AUTOSAR XML (schema 4-3-0)
package /E3_1_2_Premium
  system System: pnc-vector-length=7, pnc-vector-offset=1
    system mapping System_Mappings
      data-mappings:
        communication-direction=OUT, data-element=Infrastructure_RGS_VL_XIX_network_infrastructure_XIX_RGS_VL.Geltungsbereich_E3_1_2_Premium.SP_IF_NM_RGS_VL_Wakeup_XIX_Infrastructure_RGS_VL_XIX_network_infrastructure_XIX_RGS_VL.DE_NM_RGS_VL_Wakeup, system-signal=NM_RGS_VL_Wakeup
        communication-direction=OUT, data-element=Infrastructure_RGS_VL_XIX_network_infrastructure_XIX_RGS_VL.Geltungsbereich_E3_1_2_Premium.SP_IF_NM_RGS_VL_NM_aktiv_Diag_XIX_Infrastructure_RGS_VL_XIX_network_infrastructure_XIX_RGS_VL.DE_NM_RGS_VL_NM_aktiv_Diag, system-signal=NM_RGS_VL_NM_aktiv_Diag
        communication-direction=OUT, data-element=Infrastructure_RGS_VL_XIX_network_infrastructure_XIX_RGS_VL.Geltungsbereich_E3_1_2_Premium.SP_IF_NM_RGS_VL_FCAB_XIX_Infrastructure_RGS_VL_XIX_network_infrastructure_XIX_RGS_VL.DE_NM_RGS_VL_FCAB, system-signal=NM_RGS_VL_FCAB
        communication-direction=OUT, data-element=Infrastructure_RGS_VL_XIX_network_infrastructure_XIX_RGS_VL.Geltungsbereich_E3_1_2_Premium.SP_IF_NM_RGS_VL_NM_aktiv_KL15_XIX_Infrastructure_RGS_VL_XIX_network_infrastructure_XIX_RGS_VL.DE_NM_RGS_VL_NM_aktiv_KL15, system-signal=NM_RGS_VL_NM_aktiv_KL15
        communication-direction=OUT, data-element=Infrastructure_RGS_VL_XIX_network_infrastructure_XIX_RGS_VL.Geltungsbereich_E3_1_2_Premium.SP_IF_NM_RGS_VL_CBV_AWB_XIX_Infrastructure_RGS_VL_XIX_network_infrastructure_XIX_RGS_VL.DE_NM_RGS_VL_CBV_AWB, system-signal=NM_RGS_VL_CBV_AWB
        communication-direction=OUT, data-element=Infrastructure_RGS_VL_XIX_network_infrastructure_XIX_RGS_VL.Geltungsbereich_E3_1_2_Premium.SP_IF_NM_RGS_VL_CBV_CRI_XIX_Infrastructure_RGS_VL_XIX_network_infrastructure_XIX_RGS_VL.DE_NM_RGS_VL_CBV_CRI, system-signal=NM_RGS_VL_CBV_CRI
        communication-direction=OUT, data-element=Infrastructure_RGS_VL_XIX_network_infrastructure_XIX_RGS_VL.Geltungsbereich_E3_1_2_Premium.SP_IF_NM_RGS_VL_NM_aktiv_Tmin_XIX_Infrastructure_RGS_VL_XIX_network_infrastructure_XIX_RGS_VL.DE_NM_RGS_VL_NM_aktiv_Tmin, system-signal=NM_RGS_VL_NM_aktiv_Tmin
        communication-direction=OUT, data-element=Infrastructure_RGS_VL_XIX_network_infrastructure_XIX_RGS_VL.Geltungsbereich_E3_1_2_Premium.SP_IF_NM_RGS_VL_UDS_CC_XIX_Infrastructure_RGS_VL_XIX_network_infrastructure_XIX_RGS_VL.DE_NM_RGS_VL_UDS_CC, system-signal=NM_RGS_VL_UDS_CC
        communication-direction=OUT, data-element=Infrastructure_RGS_VL_XIX_network_infrastructure_XIX_RGS_VL.Geltungsbereich_E3_1_2_Premium.SP_IF_NM_RGS_VL_NM_State_XIX_Infrastructure_RGS_VL_XIX_network_infrastructure_XIX_RGS_VL.DE_NM_RGS_VL_NM_State, system-signal=NM_RGS_VL_NM_State
        communication-direction=OUT, data-element=Infrastructure_RGS_VL_XIX_network_infrastructure_XIX_RGS_VL.Geltungsbereich_E3_1_2_Premium.SP_IF_NM_RGS_VL_FCIB_XIX_Infrastructure_RGS_VL_XIX_network_infrastructure_XIX_RGS_VL.DE_NM_RGS_VL_FCIB, system-signal=NM_RGS_VL_FCIB
        communication-direction=OUT, data-element=Infrastructure_RGS_VL_XIX_network_infrastructure_XIX_RGS_VL.Geltungsbereich_E3_1_2_Premium.SP_IF_KN_RGS_VL_ECUKnockOutTimer_XIX_Infrastructure_RGS_VL_XIX_network_infrastructure_XIX_RGS_VL.DE_KN_RGS_VL_ECUKnockOutTimer, system-signal=KN_RGS_VL_ECUKnockOutTimer
        communication-direction=OUT, data-element=Infrastructure_RGS_VL_XIX_network_infrastructure_XIX_RGS_VL.Geltungsbereich_E3_1_2_Premium.SP_IF_KN_RGS_VL_BusKnockOut_XIX_Infrastructure_RGS_VL_XIX_network_infrastructure_XIX_RGS_VL.DE_KN_RGS_VL_BusKnockOut, system-signal=KN_RGS_VL_BusKnockOut
        communication-direction=OUT, data-element=Infrastructure_RGS_VL_XIX_network_infrastructure_XIX_RGS_VL.Geltungsbereich_E3_1_2_Premium.SP_IF_KN_RGS_VL_ECUKnockOut_XIX_Infrastructure_RGS_VL_XIX_network_infrastructure_XIX_RGS_VL.DE_KN_RGS_VL_ECUKnockOut, system-signal=KN_RGS_VL_ECUKnockOut
        communication-direction=OUT, data-element=Infrastructure_RGS_VL_XIX_network_infrastructure_XIX_RGS_VL.Geltungsbereich_E3_1_2_Premium.SP_IF_KN_RGS_VL_BusKnockOutTimer_XIX_Infrastructure_RGS_VL_XIX_network_infrastructure_XIX_RGS_VL.DE_KN_RGS_VL_BusKnockOutTimer, system-signal=KN_RGS_VL_BusKnockOutTimer
        communication-direction=IN, data-element=Infrastructure_RGS_VL_XIX_network_infrastructure_XIX_RGS_VL.Geltungsbereich_E3_1_2_Premium.RP_IF_NM_Airbag_01_FCAB_XIX_Infrastructure_RGS_VL_XIX_network_infrastructure_XIX_RGS_VL.DE_NM_Airbag_01_FCAB, system-signal=NM_Airbag_01_FCAB
        communication-direction=OUT, data-element=Infrastructure_RGS_VL_XIX_network_infrastructure_XIX_RGS_VL.Geltungsbereich_E3_1_2_Premium.SP_IF_NM_RGS_VL_SNI_10_XIX_Infrastructure_RGS_VL_XIX_network_infrastructure_XIX_RGS_VL.DE_NM_RGS_VL_SNI_10, system-signal=NM_RGS_VL_SNI_10
        communication-direction=OUT, data-element=Infrastructure_RGS_VL_XIX_network_infrastructure_XIX_RGS_VL.Geltungsbereich_E3_1_2_Premium.SP_IF_RGS_VL_Nachlauftyp_XIX_Infrastructure_RGS_VL_XIX_network_infrastructure_XIX_RGS_VL.DE_RGS_VL_Nachlauftyp, system-signal=RGS_VL_Nachlauftyp
        communication-direction=OUT, data-element=Infrastructure_RGS_VL_XIX_network_infrastructure_XIX_RGS_VL.Geltungsbereich_E3_1_2_Premium.SP_IF_NM_RGS_VL_NM_aktiv_Mot_aktiv_XIX_Infrastructure_RGS_VL_XIX_network_infrastructure_XIX_RGS_VL.DE_NM_RGS_VL_NM_aktiv_Mot_aktiv, system-signal=NM_RGS_VL_NM_aktiv_Mot_aktiv
        communication-direction=OUT, data-element=ReversiblenGurtStraffen_VL_XIX_Gurtfunktionen_XIX_RGS_VL.Geltungsbereich_E3_1_2_Premium.SP_IF_RGS_VL_Gurtgeschwindigkeit_XIX_ReversiblenGurtStraffen_VL_XIX_Gurtfunktionen_XIX_RGS_VL.DE_RGS_VL_Gurtgeschwindigkeit, system-signal=RGS_VL_Gurtgeschwindigkeit
        communication-direction=OUT, data-element=ReversiblenGurtStraffen_VL_XIX_Gurtfunktionen_XIX_RGS_VL.Geltungsbereich_E3_1_2_Premium.SP_IF_RGS_VL_Gurtbandauszug_XIX_ReversiblenGurtStraffen_VL_XIX_Gurtfunktionen_XIX_RGS_VL.DE_RGS_VL_Gurtbandauszug, system-signal=RGS_VL_Gurtbandauszug
        communication-direction=OUT, data-element=ReversiblenGurtStraffen_VL_XIX_Gurtfunktionen_XIX_RGS_VL.Geltungsbereich_E3_1_2_Premium.SP_IF_RGS_VL_InPos_XIX_ReversiblenGurtStraffen_VL_XIX_Gurtfunktionen_XIX_RGS_VL.DE_RGS_VL_InPos, system-signal=RGS_VL_InPos
        communication-direction=OUT, data-element=ReversiblenGurtStraffen_VL_XIX_Gurtfunktionen_XIX_RGS_VL.Geltungsbereich_E3_1_2_Premium.SP_IF_RGS_VL_Kommunikationsfehler_ASG_XIX_ReversiblenGurtStraffen_VL_XIX_Gurtfunktionen_XIX_RGS_VL.DE_RGS_VL_Kommunikationsfehler_ASG, system-signal=RGS_VL_Kommunikationsfehler_ASG
        communication-direction=OUT, data-element=ReversiblenGurtStraffen_VL_XIX_Gurtfunktionen_XIX_RGS_VL.Geltungsbereich_E3_1_2_Premium.SP_IF_RGS_VL_Crashabschaltung_XIX_ReversiblenGurtStraffen_VL_XIX_Gurtfunktionen_XIX_RGS_VL.DE_RGS_VL_Crashabschaltung, system-signal=RGS_VL_Crashabschaltung
        communication-direction=OUT, data-element=ReversiblenGurtStraffen_VL_XIX_Gurtfunktionen_XIX_RGS_VL.Geltungsbereich_E3_1_2_Premium.SP_IF_RGS_VL_Temp_XIX_ReversiblenGurtStraffen_VL_XIX_Gurtfunktionen_XIX_RGS_VL.DE_RGS_VL_Temp, system-signal=RGS_VL_Temp
        communication-direction=OUT, data-element=ReversiblenGurtStraffen_VL_XIX_Gurtfunktionen_XIX_RGS_VL.Geltungsbereich_E3_1_2_Premium.SP_IF_RGS_VL_keineStraffungUnterspg_XIX_ReversiblenGurtStraffen_VL_XIX_Gurtfunktionen_XIX_RGS_VL.DE_RGS_VL_keineStraffungUnterspg, system-signal=RGS_VL_keineStraffungUnterspg
        communication-direction=OUT, data-element=ReversiblenGurtStraffen_VL_XIX_Gurtfunktionen_XIX_RGS_VL.Geltungsbereich_E3_1_2_Premium.SP_IF_RGS_VL_Unterspannung_XIX_ReversiblenGurtStraffen_VL_XIX_Gurtfunktionen_XIX_RGS_VL.DE_RGS_VL_Unterspannung, system-signal=RGS_VL_Unterspannung
        communication-direction=OUT, data-element=ReversiblenGurtStraffen_VL_XIX_Gurtfunktionen_XIX_RGS_VL.Geltungsbereich_E3_1_2_Premium.SP_IF_RGS_VL_Uebertemperatur_defekt_XIX_ReversiblenGurtStraffen_VL_XIX_Gurtfunktionen_XIX_RGS_VL.DE_RGS_VL_Uebertemperatur_defekt, system-signal=RGS_VL_Uebertemperatur_defekt
        communication-direction=OUT, data-element=ReversiblenGurtStraffen_VL_XIX_Gurtfunktionen_XIX_RGS_VL.Geltungsbereich_E3_1_2_Premium.SP_IF_RGS_VL_EEPROM_Datensatzfehler_XIX_ReversiblenGurtStraffen_VL_XIX_Gurtfunktionen_XIX_RGS_VL.DE_RGS_VL_EEPROM_Datensatzfehler, system-signal=RGS_VL_EEPROM_Datensatzfehler
        communication-direction=OUT, data-element=ReversiblenGurtStraffen_VL_XIX_Gurtfunktionen_XIX_RGS_VL.Geltungsbereich_E3_1_2_Premium.SP_IF_RGS_VL_nicht_programmiert_XIX_ReversiblenGurtStraffen_VL_XIX_Gurtfunktionen_XIX_RGS_VL.DE_RGS_VL_nicht_programmiert, system-signal=RGS_VL_nicht_programmiert
        communication-direction=OUT, data-element=ReversiblenGurtStraffen_VL_XIX_Gurtfunktionen_XIX_RGS_VL.Geltungsbereich_E3_1_2_Premium.SP_IF_RGS_VL_Bauteilfehler_XIX_ReversiblenGurtStraffen_VL_XIX_Gurtfunktionen_XIX_RGS_VL.DE_RGS_VL_Bauteilfehler, system-signal=RGS_VL_Bauteilfehler
        communication-direction=OUT, data-element=ReversiblenGurtStraffen_VL_XIX_Gurtfunktionen_XIX_RGS_VL.Geltungsbereich_E3_1_2_Premium.SP_IF_RGS_VL_Max_Gurtlosezyklen_XIX_ReversiblenGurtStraffen_VL_XIX_Gurtfunktionen_XIX_RGS_VL.DE_RGS_VL_Max_Gurtlosezyklen, system-signal=RGS_VL_Max_Gurtlosezyklen
        communication-direction=OUT, data-element=ReversiblenGurtStraffen_VL_XIX_Gurtfunktionen_XIX_RGS_VL.Geltungsbereich_E3_1_2_Premium.SP_IF_RGS_VL_Ueberspannung_XIX_ReversiblenGurtStraffen_VL_XIX_Gurtfunktionen_XIX_RGS_VL.DE_RGS_VL_Ueberspannung, system-signal=RGS_VL_Ueberspannung
        communication-direction=OUT, data-element=ReversiblenGurtStraffen_VL_XIX_Gurtfunktionen_XIX_RGS_VL.Geltungsbereich_E3_1_2_Premium.SP_IF_RGS_VL_Motorfehler_XIX_ReversiblenGurtStraffen_VL_XIX_Gurtfunktionen_XIX_RGS_VL.DE_RGS_VL_Motorfehler, system-signal=RGS_VL_Motorfehler
        communication-direction=OUT, data-element=ReversiblenGurtStraffen_VL_XIX_Gurtfunktionen_XIX_RGS_VL.Geltungsbereich_E3_1_2_Premium.SP_IF_RGS_VL_Strom_XIX_ReversiblenGurtStraffen_VL_XIX_Gurtfunktionen_XIX_RGS_VL.DE_RGS_VL_Strom, system-signal=RGS_VL_Strom
        communication-direction=OUT, data-element=ReversiblenGurtStraffen_VL_XIX_Gurtfunktionen_XIX_RGS_VL.Geltungsbereich_E3_1_2_Premium.SP_IF_RGS_VL_Status_XIX_ReversiblenGurtStraffen_VL_XIX_Gurtfunktionen_XIX_RGS_VL.DE_RGS_VL_Status, system-signal=RGS_VL_Status
        communication-direction=OUT, data-element=ReversiblenGurtStraffen_VL_XIX_Gurtfunktionen_XIX_RGS_VL.Geltungsbereich_E3_1_2_Premium.SP_IF_RGS_VL_Max_Haptikzyklenfehler_XIX_ReversiblenGurtStraffen_VL_XIX_Gurtfunktionen_XIX_RGS_VL.DE_RGS_VL_Max_Haptikzyklenfehler, system-signal=RGS_VL_Max_Haptikzyklenfehler
        communication-direction=OUT, data-element=ReversiblenGurtStraffen_VL_XIX_Gurtfunktionen_XIX_RGS_VL.Geltungsbereich_E3_1_2_Premium.SP_IF_RGS_VL_Max_Straffzyklenfehler_XIX_ReversiblenGurtStraffen_VL_XIX_Gurtfunktionen_XIX_RGS_VL.DE_RGS_VL_Max_Straffzyklenfehler, system-signal=RGS_VL_Max_Straffzyklenfehler
        communication-direction=OUT, data-element=ReversiblenGurtStraffen_VL_XIX_Gurtfunktionen_XIX_RGS_VL.Geltungsbereich_E3_1_2_Premium.SP_IF_RGS_VL_keineStraffungUeberspg_XIX_ReversiblenGurtStraffen_VL_XIX_Gurtfunktionen_XIX_RGS_VL.DE_RGS_VL_keineStraffungUeberspg, system-signal=RGS_VL_keineStraffungUeberspg
        communication-direction=IN, data-element=ReversiblenGurtStraffen_VL_XIX_Gurtfunktionen_XIX_RGS_VL.Geltungsbereich_E3_1_2_Premium.RP_IF_RGS_VL_Anforderung_XIX_ReversiblenGurtStraffen_VL_XIX_Gurtfunktionen_XIX_RGS_VL.DE_RGS_VL_Anforderung, system-signal=RGS_VL_Anforderung
        communication-direction=IN, data-element=ReversiblenGurtStraffen_VL_XIX_Gurtfunktionen_XIX_RGS_VL.Geltungsbereich_E3_1_2_Premium.RP_IF_RGS_Nachlauf_allg_XIX_ReversiblenGurtStraffen_VL_XIX_Gurtfunktionen_XIX_RGS_VL.DE_RGS_Nachlauf_allg, system-signal=RGS_Nachlauf_allg
        communication-direction=IN, data-element=ReversiblenGurtStraffen_VL_XIX_Gurtfunktionen_XIX_RGS_VL.Geltungsbereich_E3_1_2_Premium.RP_IF_RGS_VL_Nachlauf_2_XIX_ReversiblenGurtStraffen_VL_XIX_Gurtfunktionen_XIX_RGS_VL.DE_RGS_VL_Nachlauf_2, system-signal=RGS_VL_Nachlauf_2
      pnc-mappings:
        pnc-identifier=8, wakeup-frame=[FT_NM_Airbag, FT_NM_RGS_VL]
        pnc-group=[RGS_VL_XIX_PNC_13_Airbag_Rx, RGS_VL_XIX_PNC_13_Airbag_Tx], pnc-identifier=20
      sw-mappings:
        swc to ecu mapping MAPPING_Infrastructure_RGS_VL_XIX_network_infrastructure_XIX_RGS_VL: component=Geltungsbereich_E3_1_2_Premium.Infrastructure_RGS_VL_XIX_network_infrastructure_XIX_RGS_VL, ecu-instance=RGS_VL
        swc to ecu mapping MAPPING_ReversiblenGurtStraffen_VL_XIX_Gurtfunktionen_XIX_RGS_VL: component=Geltungsbereich_E3_1_2_Premium.ReversiblenGurtStraffen_VL_XIX_Gurtfunktionen_XIX_RGS_VL, ecu-instance=RGS_VL
    root-software-compositions:
      root sw composition prototype Geltungsbereich_E3_1_2_Premium: software-composition=Geltungsbereich_E3_1_2_Premium
package /ECU
  ecu instance RGS_VL: associated-com-i-pdu-group=[RGS_VL_XIX_Airbag_SUBCANFD01_Rx, RGS_VL_XIX_Airbag_SUBCANFD01_Tx, RGS_VL_XIX_PNC_13_Airbag_Rx, RGS_VL_XIX_PNC_13_Airbag_Tx], diagnostic-address=1578, sleep-mode-supported=true, wake-up-over-bus-supported=true  # Reversibler Gurtstraffer vorn links
    can communication controller CT_Airbag_SUBCANFD01: can-controller-attributes=can-controller-configuration-requirements={can-controller-fd-requirements={max-number-of-time-quanta-per-bit=20, max-sample-point=80.0, max-sync-jump-width=20.0, max-trcv-delay-compensation-offset=80.0, min-number-of-time-quanta-per-bit=20, min-sample-point=80.0, min-sync-jump-width=20.0, min-trcv-delay-compensation-offset=80.0}, max-number-of-time-quanta-per-bit=20, max-sample-point=80.0, max-sync-jump-width=20.0, min-number-of-time-quanta-per-bit=20, min-sample-point=80.0, min-sync-jump-width=20.0}
    can communication connector CN_Airbag_SUBCANFD01: comm-controller=CT_Airbag_SUBCANFD01, pnc-gateway-type=NONE
package /Cluster
  can cluster Airbag_SUBCANFD01: baudrate=500000, protocol-name=CAN, protocol-version=2.0, can-fd-baudrate=500000  # Datenbus Erweitertes Sicherheitssystem
    can physical channel CHNL: comm-connectors=CN_Airbag_SUBCANFD01
      frame DIA_RGS_VL_Req_XIX_Airbag_SUBCANFD01: id 0x17FC162A, to RGS_VL, frame-length=8, can-addressing-mode=EXTENDED, can-fd-frame-support=true, can-frame-rx-behavior=CAN-FD, can-frame-tx-behavior=CAN-FD
        n pdu DIA_RGS_VL_Req_XIX_Airbag_SUBCANFD01: length=8
      frame DIA_RGS_VL_Resp_XIX_Airbag_SUBCANFD01: id 0x17FE162A, from RGS_VL, frame-length=8, can-addressing-mode=EXTENDED, can-fd-frame-support=true, can-frame-rx-behavior=CAN-FD, can-frame-tx-behavior=CAN-FD
        n pdu DIA_RGS_VL_Resp_XIX_Airbag_SUBCANFD01: length=8
      frame KN_RGS_VL_XIX_Airbag_SUBCANFD01: id 0x17F0005E, from RGS_VL, frame-length=16, can-addressing-mode=EXTENDED, can-fd-frame-support=true, can-frame-rx-behavior=CAN-FD, can-frame-tx-behavior=CAN-FD
        pdu KN_RGS_VL_XIX_Airbag_SUBCANFD01: length=16, transmission-mode-true-timing=cyclic-timing={time-offset=0.0, time-period=0.2}, unused-bit-pattern=0
          signal KN_RGS_VL_BusKnockOut_XIX_KN_RGS_VL_XIX_Airbag_SUBCANFD01: start 30, 2 bit, little-endian, data-type-policy=OVERRIDE, i-signal-type=PRIMITIVE, init-value=0, base-type=uint8, implementation-data-type=DT_KN_RGS_VL_BusKnockOut_XIX_KN_RGS_VL_XIX_Airbag_SUBCANFD01, compu {0=Cx0_Funktion_nicht_ausgeloest, 1=Cx1_Veto_aktiv, 3=Cx3_Funktion_deaktiviert, 2=Cx2_Funktion_ausgeloest}, range raw 0..3, transfer-property=PENDING  # Ausgabe des BusKnockout-Status
          signal KN_RGS_VL_BusKnockOutTimer_XIX_KN_RGS_VL_XIX_Airbag_SUBCANFD01: start 32, 8 bit, little-endian, data-type-policy=OVERRIDE, i-signal-type=PRIMITIVE, init-value=0, base-type=uint8, implementation-data-type=DT_KN_RGS_VL_BusKnockOutTimer_XIX_KN_RGS_VL_XIX_Airbag_SUBCANFD01, compu {phys=raw for raw 0..254, 255=Cxff_BusKnockOut_deaktiviert}, range phys 0..254, raw 0..255, transfer-property=PENDING  # Ausgabe des BusKnockOut-Timer
          signal KN_RGS_VL_ECUKnockOut_XIX_KN_RGS_VL_XIX_Airbag_SUBCANFD01: start 18, 2 bit, little-endian, data-type-policy=OVERRIDE, i-signal-type=PRIMITIVE, init-value=0, base-type=uint8, implementation-data-type=DT_KN_RGS_VL_ECUKnockOut_XIX_KN_RGS_VL_XIX_Airbag_SUBCANFD01, compu {2=Cx2_Funktion_ausgeloest, 3=Cx3_Funktion_deaktiviert, 1=Cx1_Veto_war_aktiv, 0=Cx0_Funktion_nicht_ausgeloest}, range raw 0..3, transfer-property=PENDING  # Ausgabe des ECUKnockout-Status
          signal KN_RGS_VL_ECUKnockOutTimer_XIX_KN_RGS_VL_XIX_Airbag_SUBCANFD01: start 24, 6 bit, little-endian, data-type-policy=OVERRIDE, i-signal-type=PRIMITIVE, init-value=0, base-type=uint8, implementation-data-type=DT_KN_RGS_VL_ECUKnockOutTimer_XIX_KN_RGS_VL_XIX_Airbag_SUBCANFD01, compu {phys=raw for raw 0..62, 63=Cx3f_ECUKnockOut_deaktiviert}, range phys 0..62, raw 0..63, transfer-property=PENDING  # Ausgabe des ECUKnockOut-Timer
          signal NM_RGS_VL_FCIB_XIX_KN_RGS_VL_XIX_Airbag_SUBCANFD01: start 40, 56 bit, opaque, data-type-policy=OVERRIDE, i-signal-type=ARRAY, init-value=7 x 0, base-type=uint8, implementation-data-type=DT_NM_RGS_VL_FCIB_XIX_KN_RGS_VL_XIX_Airbag_SUBCANFD01, compu {128=Cx80_reserviert, 8388608=Cx800000_Laden, 2048=Cx800_Airbag, 1=Cx1_CarWakeUp, 131072=Cx20000_Komfort2, 32768=Cx8000_Nahbereichszugang, 2=Cx2_Basisfunktion_AntriebFahrwerk, 0=Cx0_Init, 33554432=Cx2000000_MV_Aktivierung, 262144=Cx40000_Warnlampen, 512=Cx200_Fahrwerk, 256=Cx100_Antrieb, 1024=Cx400_Waehlhebel, 65536=Cx10000_Komfort1, 2097152=Cx200000_Thermomaagement, 16384=Cx4000_Sound, 4096=Cx1000_Fahrerassistenz, 2147483648=Cx80000000_reserviert, 8192=Cx2000_Displays, 4194304=Cx400000_VirtuelleAussenspiegel, 67108864=Cx4000000_Timermaster_Timer, 1073741824=Cx40000000_reserviert, 16777216=Cx1000000_HV_Aktivierung, 524288=Cx80000_Beleuchtung, 536870912=Cx20000000_reserviert, 268435456=Cx10000000_Multifunktionslankrad, 134217728=Cx8000000_Onboard_Tester_OBDC, 16=Cx10_Basisfunktion_KomfortKlimaLicht, 1048576=Cx100000_Innenklimatisierung, 32=Cx20_Basisfunktion_Querschnitt, 4=Cx4_Basisfunktion_Fahrerassistenz, 64=Cx40_Basisfunktion_Konnektivitaet, 8=Cx8_Basisfunktion_Infotainment}, range raw 0..2147483648, transfer-property=PENDING  # FCIB = Funktions-Cluster-Initialisierungs-Bits
          signal RGS_VL_Abschaltstufe_XIX_KN_RGS_VL_XIX_Airbag_SUBCANFD01: start 1, 1 bit, little-endian, data-type-policy=OVERRIDE, i-signal-type=PRIMITIVE, init-value=0, base-type=uint8, implementation-data-type=DT_RGS_VL_Abschaltstufe_XIX_KN_RGS_VL_XIX_Airbag_SUBCANFD01, compu {0=Cx0_keine_Einschraenkung, 1=Cx1_Funktionseinschraenkung}, range raw 0..1, transfer-property=PENDING  # Funktionseinschränkung aufgrund aktiver Abschaltstufe
          signal RGS_VL_KD_Fehler_XIX_KN_RGS_VL_XIX_Airbag_SUBCANFD01: start 23, 1 bit, little-endian, data-type-policy=OVERRIDE, i-signal-type=PRIMITIVE, init-value=0, base-type=uint8, implementation-data-type=DT_RGS_VL_KD_Fehler_XIX_KN_RGS_VL_XIX_Airbag_SUBCANFD01, compu {1=Cx1_KD_Fehler, 0=Cx0_kein_KD_Fehler}, range raw 0..1, transfer-property=PENDING
          signal RGS_VL_KompSchutz_XIX_KN_RGS_VL_XIX_Airbag_SUBCANFD01: start 0, 1 bit, little-endian, data-type-policy=OVERRIDE, i-signal-type=PRIMITIVE, init-value=0, base-type=uint8, implementation-data-type=DT_RGS_VL_KompSchutz_XIX_KN_RGS_VL_XIX_Airbag_SUBCANFD01, compu {1=Cx1_aktiv, 0=Cx0_inaktiv}, range raw 0..1, transfer-property=PENDING  # Funktionseinschränkung aufgrund Komponentenschutz aktiv
          signal RGS_VL_Lokalaktiv_XIX_KN_RGS_VL_XIX_Airbag_SUBCANFD01: start 21, 1 bit, little-endian, data-type-policy=OVERRIDE, i-signal-type=PRIMITIVE, init-value=0, base-type=uint8, implementation-data-type=DT_RGS_VL_Lokalaktiv_XIX_KN_RGS_VL_XIX_Airbag_SUBCANFD01, compu {0=Cx0_war_nicht_lokal_aktiv, 1=Cx1_war_lokal_aktiv}, range raw 0..1, transfer-property=PENDING  # Zeigt an ob das SG nach Klemme15 AUS und nach entsprechender MAX Aktivzeit noch aktiv war
          signal RGS_VL_Nachlauftyp_XIX_KN_RGS_VL_XIX_Airbag_SUBCANFD01: start 4, 4 bit, little-endian, data-type-policy=OVERRIDE, i-signal-type=PRIMITIVE, init-value=0, base-type=uint8, implementation-data-type=DT_RGS_VL_Nachlauftyp_XIX_KN_RGS_VL_XIX_Airbag_SUBCANFD01, compu {1=Cx1_Komm_nach_KL15_AUS, 2=Cx2_Komm_bei_KL15_AUS, 0=Cx0_Komm_bei_KL15_EIN}, range raw 0..2, transfer-property=PENDING  # Abgebildet wird die von der Hardware vorgegebene Möglichkeit, die Kommunikation nach Klemme 15 = AUS aufrecht zu erhalten. Es wird ein Init-Wert gesendet. 0 = Kommunikation nur bei KL15=EIN (kein Nachlauf, nicht weckfähig) 1 = Kommunikation nach KL15=AUS (Nachlauf, nicht weckfähig) 2 = Kommunikation bei KL15=AUS (Nachlauf, weckfähig) 3...15 = reserviert
          signal RGS_VL_SNI_10_XIX_KN_RGS_VL_XIX_Airbag_SUBCANFD01: start 8, 10 bit, little-endian, data-type-policy=OVERRIDE, i-signal-type=PRIMITIVE, init-value=94, base-type=uint16, implementation-data-type=DT_RGS_VL_SNI_10_XIX_KN_RGS_VL_XIX_Airbag_SUBCANFD01, compu {94=Cx5e_RGS_VL_SNI}, range raw 94, transfer-property=PENDING  # Source Node-Identifier (SNI) identifiziert den Sender der NM-Botschaft (Knotenadresse) eindeutig im Fahrzeug
          signal RGS_VL_Subsystemaktiv_XIX_KN_RGS_VL_XIX_Airbag_SUBCANFD01: start 22, 1 bit, little-endian, data-type-policy=OVERRIDE, i-signal-type=PRIMITIVE, init-value=0, base-type=uint8, implementation-data-type=DT_RGS_VL_Subsystemaktiv_XIX_KN_RGS_VL_XIX_Airbag_SUBCANFD01, compu {0=Cx0_Subsystem_war_nicht_lokalaktiv, 1=Cx1_war_lokalaktiv}, range raw 0..1, transfer-property=PENDING  # Zeigt an ob ein Subsystem des SGs nach Klemme15 AUS und nach entsprechender MAX Aktivzeit noch aktiv war
          signal RGS_VL_Transport_Mode_XIX_KN_RGS_VL_XIX_Airbag_SUBCANFD01: start 2, 1 bit, little-endian, data-type-policy=OVERRIDE, i-signal-type=PRIMITIVE, init-value=0, base-type=uint8, implementation-data-type=DT_RGS_VL_Transport_Mode_XIX_KN_RGS_VL_XIX_Airbag_SUBCANFD01, compu {0=Cx0_keine_Einschraenkung, 1=Cx1_Funktionseinschraenkung}, range raw 0..1, transfer-property=PENDING  # Funktionseinschränkung aufgrund aktivem Transport Mode und/oder Transport Schutz
      frame NM_Airbag_XIX_Airbag_SUBCANFD01: id 0x1B000015, to RGS_VL, frame-length=24, can-addressing-mode=EXTENDED, can-fd-frame-support=true, can-frame-rx-behavior=CAN-FD, can-frame-tx-behavior=CAN-FD, rx-identifier-range={lower-can-id=452984832, upper-can-id=452985855}
        nm pdu NM_Airbag_XIX_Airbag_SUBCANFD01: length=24
          signal NM_Airbag_01_CBV_AWB_XIX_NM_Airbag_XIX_Airbag_SUBCANFD01: start 4, 1 bit, little-endian, data-type-policy=OVERRIDE, i-signal-type=PRIMITIVE, init-value=0, base-type=uint8, implementation-data-type=DT_NM_Airbag_01_CBV_AWB_XIX_NM_Airbag_XIX_Airbag_SUBCANFD01, compu {1=Cx1_Aktiver_WakeUp, 0=Cx0_Passiver_WakeUp}, range raw 0..1, transfer-property=TRIGGERED  # Das Signal ist zu setzen, wenn das SG aktiv den Bus geweckt hat 0 = Passiver_WakeUp = SG hat das Netzwerk nicht aktiv geweckt 1 = Akitiver_WakeUp = SG hat das Netzwerk aktiv geweckt
          signal NM_Airbag_01_CBV_CRI_XIX_NM_Airbag_XIX_Airbag_SUBCANFD01: start 6, 1 bit, little-endian, data-type-policy=OVERRIDE, i-signal-type=PRIMITIVE, init-value=1, base-type=uint8, implementation-data-type=DT_NM_Airbag_01_CBV_CRI_XIX_NM_Airbag_XIX_Airbag_SUBCANFD01, compu {0=Cx0_NM_ohne_Clusteranforderungen, 1=Cx1_NM_mit_Clusteranforderungen}, range raw 0..1, transfer-property=TRIGGERED  # Das Signal ist dauerhaft gesetzt, wenn das NM-Layout Cluster- Anforderungen enthält
          signal NM_Airbag_01_FCAB_XIX_NM_Airbag_XIX_Airbag_SUBCANFD01: start 8, 56 bit, opaque, data-type-policy=OVERRIDE, i-signal-type=ARRAY, init-value=7 x 0, base-type=uint8, compu {8=Cx8_04_Basefunction_DrivingAssistance, 32=Cx20_06_Basefunction_ComfortLight, 4194304=Cx400000_23_Climate_PreHeater, 1048576=Cx100000_21_AirSuspension, 4096=Cx1000_13_Airbag, 524288=Cx80000_20_OptionalComfort, 4=Cx4_03_Basefunction_Chassis, 4294967296=Cx100000000_33_ExternalWirelessCommunication, 8388608=Cx800000_24_ThermoManagement, 2147483648=Cx80000000_32_OnlineAccess, 16777216=Cx1000000_25_AccessSystemSensors, 1024=Cx400_11_Chassis, 65536=Cx10000_17_Audio, 1073741824=Cx40000000_31_MultifunctionalSteeringWheel, 2097152=Cx200000_22_ExteriorLights, 8192=Cx2000_14_InfotainmentExtensions, 18014398509481984=Cx40000000000000_55_Dimming, 134217728=Cx8000000_28_OnboardTester_DataCollector, 36028797018963968=Cx80000000000000_56_ChargingStatus, 2048=Cx800_12_GearSelector, 2=Cx2_02_Basefunction_Powertrain, 16384=Cx4000_15_InstrumentclusterDisplay, 256=Cx100_09_reserved, 131072=Cx20000_18_VirtualSideMirrors, 17179869184=Cx400000000_53_Lock_Unlock, 33554432=Cx2000000_26_HighVoltage_Charging, 536870912=Cx20000000_30_EnergyManagement, 67108864=Cx4000000_27_Timemaster_Timer, 1=Cx1_01_CarWakeUp, 512=Cx200_10_Powertrain, 0=Cx0_Init, 262144=Cx40000_19_Doors_Hatches, 128=Cx80_08_Basefunction_Connectivity, 8589934592=Cx200000000_34_GPS_Localization, 64=Cx40_07_Basefunction_CrossSection, 32768=Cx8000_16_InfotainmentDisplay, 16=Cx10_05_Basefunction_Infotainment}, range raw 0..36028797018963968, transfer-property=TRIGGERED, to RGS_VL(timeout 2 s)  # FCAB = Funktions-Cluster-Aktiv-Bits
          signal NM_Airbag_01_NM_State_XIX_NM_Airbag_XIX_Airbag_SUBCANFD01: start 144, 6 bit, little-endian, data-type-policy=OVERRIDE, i-signal-type=PRIMITIVE, init-value=0, base-type=uint8, implementation-data-type=DT_NM_Airbag_01_NM_State_XIX_NM_Airbag_XIX_Airbag_SUBCANFD01, compu {16=Cx10_reserved, 2=Cx2_NM_RM_aus_PBSM, 4=Cx4_NM_NO_aus_RM, 0=Cx0_Init, 32=Cx20_reserved, 8=Cx8_NM_NO_aus_RS, 1=Cx1_NM_RM_aus_BSM}, range raw 0..32, transfer-property=TRIGGERED  # 1 = Zustand Repeat Message (<-- Bus-Sleep Mode) 2 = Zustand Repeat Message (<-- Prepare Bus-Sleep Mode) 4 = Zustand Normal Operation (<-- Repeat Message) 8 = Zustand Normal Operation (<-- Ready Sleep)
          signal NM_Airbag_01_NM_aktiv_Diag_XIX_NM_Airbag_XIX_Airbag_SUBCANFD01: start 161, 1 bit, little-endian, data-type-policy=OVERRIDE, i-signal-type=PRIMITIVE, init-value=0, base-type=uint8, implementation-data-type=DT_NM_Airbag_01_NM_aktiv_Diag_XIX_NM_Airbag_XIX_Airbag_SUBCANFD01, compu {1=Cx1_Diagnose_aktiv, 0=Cx0_Inaktiv}, range raw 0..1, transfer-property=TRIGGERED  # Diagnose befindet sich nach VW80124 in einer NonDefaultDiagnostic-Session, z.B. ExtendedDiagnostic-Session
          signal NM_Airbag_01_NM_aktiv_KL15_XIX_NM_Airbag_XIX_Airbag_SUBCANFD01: start 160, 1 bit, little-endian, data-type-policy=OVERRIDE, i-signal-type=PRIMITIVE, init-value=0, base-type=uint8, implementation-data-type=DT_NM_Airbag_01_NM_aktiv_KL15_XIX_NM_Airbag_XIX_Airbag_SUBCANFD01, compu {1=Cx1_KL15_EIN, 0=Cx0_Inaktiv}, range raw 0..1, transfer-property=TRIGGERED  # Steuergerät hat KL15-EIN erkannt
          signal NM_Airbag_01_NM_aktiv_Tmin_XIX_NM_Airbag_XIX_Airbag_SUBCANFD01: start 162, 1 bit, little-endian, data-type-policy=OVERRIDE, i-signal-type=PRIMITIVE, init-value=0, base-type=uint8, implementation-data-type=DT_NM_Airbag_01_NM_aktiv_Tmin_XIX_NM_Airbag_XIX_Airbag_SUBCANFD01, compu {0=Cx0_Inaktiv, 1=Cx1_Mindestaktivzeit}, range raw 0..1, transfer-property=TRIGGERED  # Mindestaktivzeit ist noch nicht abgelaufen (bei jedem Weckereignis wird die Mindestaktivzeit neu gestartet)
          signal NM_Airbag_01_SNI_10_XIX_NM_Airbag_XIX_Airbag_SUBCANFD01: start 128, 10 bit, little-endian, data-type-policy=OVERRIDE, i-signal-type=PRIMITIVE, init-value=21, base-type=uint16, implementation-data-type=DT_NM_Airbag_01_SNI_10_XIX_NM_Airbag_XIX_Airbag_SUBCANFD01, compu {21=Cx15_Airbag_01_SNI}, range raw 21, transfer-property=PENDING  # Source Node-Identifier (SNI) identifiziert den Sender der NM-Botschaft (Knotenadresse) eindeutig im Fahrzeug
          signal NM_Airbag_01_UDS_CC_XIX_NM_Airbag_XIX_Airbag_SUBCANFD01: start 151, 1 bit, little-endian, data-type-policy=OVERRIDE, i-signal-type=PRIMITIVE, init-value=0, base-type=uint8, implementation-data-type=DT_NM_Airbag_01_UDS_CC_XIX_NM_Airbag_XIX_Airbag_SUBCANFD01, compu {0=Cx0_Inaktiv, 1=Cx1_CC_aktiv}, range raw 0..1, transfer-property=TRIGGERED  # Funktionseinschränkung aufgrund aktivem UDS-Communication Control, siehe VW80124
          signal NM_Airbag_01_Wakeup_XIX_NM_Airbag_XIX_Airbag_SUBCANFD01: start 152, 8 bit, little-endian, data-type-policy=OVERRIDE, i-signal-type=PRIMITIVE, init-value=0, base-type=uint8, implementation-data-type=DT_NM_Airbag_01_Wakeup_XIX_NM_Airbag_XIX_Airbag_SUBCANFD01, compu {1=Cx1_Bus_Wakeup, 0=Cx0_Peripherie_Wakeup_Ursache_nicht_bekannt, 2=Cx2_KL15_HW}, range raw 0..2, transfer-property=TRIGGERED  # enthält die Weckursache; stehen mehrere Weckursachen parallel an, dann muss der kleinste Wert übertragen werden
          signal NM_aktiv_Ausloesefaehig_XIX_NM_Airbag_XIX_Airbag_SUBCANFD01: start 166, 1 bit, little-endian, data-type-policy=OVERRIDE, i-signal-type=PRIMITIVE, init-value=0, base-type=uint8, implementation-data-type=DT_NM_aktiv_Ausloesefaehig_XIX_NM_Airbag_XIX_Airbag_SUBCANFD01, compu {0=Cx0_Inaktiv, 1=Cx1_Aktiv}, range raw 0..1, transfer-property=TRIGGERED  # Steuergerät hat KL15-EIN erkannt
          signal NM_aktiv_Gurtschloss_XIX_NM_Airbag_XIX_Airbag_SUBCANFD01: start 167, 1 bit, little-endian, data-type-policy=OVERRIDE, i-signal-type=PRIMITIVE, init-value=0, base-type=uint8, implementation-data-type=DT_NM_aktiv_Gurtschloss_XIX_NM_Airbag_XIX_Airbag_SUBCANFD01, compu {0=Cx0_Inaktiv, 1=Cx1_Aktiv}, range raw 0..1, transfer-property=TRIGGERED  # Steuergerät hat KL15-EIN erkannt
          signal NM_aktiv_Kl15_unplausibel_XIX_NM_Airbag_XIX_Airbag_SUBCANFD01: start 164, 1 bit, little-endian, data-type-policy=OVERRIDE, i-signal-type=PRIMITIVE, init-value=0, base-type=uint8, implementation-data-type=DT_NM_aktiv_Kl15_unplausibel_XIX_NM_Airbag_XIX_Airbag_SUBCANFD01, compu {1=Cx1_Aktiv, 0=Cx0_Inaktiv}, range raw 0..1, transfer-property=TRIGGERED  # Steuergerät hat KL15-EIN erkannt
          signal NM_aktiv_Sitzbelegung_XIX_NM_Airbag_XIX_Airbag_SUBCANFD01: start 165, 1 bit, little-endian, data-type-policy=OVERRIDE, i-signal-type=PRIMITIVE, init-value=0, base-type=uint8, implementation-data-type=DT_NM_aktiv_Sitzbelegung_XIX_NM_Airbag_XIX_Airbag_SUBCANFD01, compu {0=Cx0_Inaktiv, 1=Cx1_Aktiv}, range raw 0..1, transfer-property=TRIGGERED  # Steuergerät hat KL15-EIN erkannt
      frame NM_RGS_VL_XIX_Airbag_SUBCANFD01: id 0x1B00005E, from RGS_VL, frame-length=24, can-addressing-mode=EXTENDED, can-fd-frame-support=true, can-frame-rx-behavior=CAN-FD, can-frame-tx-behavior=CAN-FD, rx-identifier-range={lower-can-id=452984832, upper-can-id=452985855}
        nm pdu NM_RGS_VL_XIX_Airbag_SUBCANFD01: length=24
          signal NM_RGS_VL_CBV_AWB_XIX_NM_RGS_VL_XIX_Airbag_SUBCANFD01: start 4, 1 bit, little-endian, data-type-policy=OVERRIDE, i-signal-type=PRIMITIVE, init-value=0, base-type=uint8, implementation-data-type=DT_NM_RGS_VL_CBV_AWB_XIX_NM_RGS_VL_XIX_Airbag_SUBCANFD01, compu {1=Cx1_Aktiver_WakeUp, 0=Cx0_Passiver_WakeUp}, range raw 0..1, transfer-property=TRIGGERED  # Das Signal ist zu setzen, wenn das SG aktiv den Bus geweckt hat 0 = Passiver_WakeUp = SG hat das Netzwerk nicht aktiv geweckt 1 = Akitiver_WakeUp = SG hat das Netzwerk aktiv geweckt
          signal NM_RGS_VL_CBV_CRI_XIX_NM_RGS_VL_XIX_Airbag_SUBCANFD01: start 6, 1 bit, little-endian, data-type-policy=OVERRIDE, i-signal-type=PRIMITIVE, init-value=1, base-type=uint8, implementation-data-type=DT_NM_RGS_VL_CBV_CRI_XIX_NM_RGS_VL_XIX_Airbag_SUBCANFD01, compu {0=Cx0_NM_ohne_Clusteranforderungen, 1=Cx1_NM_mit_Clusteranforderungen}, range raw 0..1, transfer-property=TRIGGERED  # Das Signal ist dauerhaft gesetzt, wenn das NM-Layout Cluster- Anforderungen enthält
          signal NM_RGS_VL_FCAB_XIX_NM_RGS_VL_XIX_Airbag_SUBCANFD01: start 8, 56 bit, opaque, data-type-policy=OVERRIDE, i-signal-type=ARRAY, init-value=7 x 0, base-type=uint8, implementation-data-type=DT_NM_RGS_VL_FCAB_XIX_NM_RGS_VL_XIX_Airbag_SUBCANFD01, compu {16777216=Cx1000000_25_AccessSystemSensors, 1048576=Cx100000_21_AirSuspension, 67108864=Cx4000000_27_Timemaster_Timer, 8589934592=Cx200000000_34_GPS_Localization, 8192=Cx2000_14_InfotainmentExtensions, 262144=Cx40000_19_Doors_Hatches, 128=Cx80_08_Basefunction_Connectivity, 2048=Cx800_12_GearSelector, 1024=Cx400_11_Chassis, 32768=Cx8000_16_InfotainmentDisplay, 524288=Cx80000_20_OptionalComfort, 36028797018963968=Cx80000000000000_56_ChargingStatus, 4194304=Cx400000_23_Climate_PreHeater, 2=Cx2_02_Basefunction_Powertrain, 2097152=Cx200000_22_ExteriorLights, 64=Cx40_07_Basefunction_CrossSection, 4096=Cx1000_13_Airbag, 512=Cx200_10_Powertrain, 18014398509481984=Cx40000000000000_55_Dimming, 33554432=Cx2000000_26_HighVoltage_Charging, 8388608=Cx800000_24_ThermoManagement, 256=Cx100_09_reserved, 17179869184=Cx400000000_53_Lock_Unlock, 4=Cx4_03_Basefunction_Chassis, 32=Cx20_06_Basefunction_ComfortLight, 536870912=Cx20000000_30_EnergyManagement, 65536=Cx10000_17_Audio, 1073741824=Cx40000000_31_MultifunctionalSteeringWheel, 8=Cx8_04_Basefunction_DrivingAssistance, 16384=Cx4000_15_InstrumentclusterDisplay, 1=Cx1_01_CarWakeUp, 2147483648=Cx80000000_32_OnlineAccess, 134217728=Cx8000000_28_OnboardTester_DataCollector, 131072=Cx20000_18_VirtualSideMirrors, 4294967296=Cx100000000_33_ExternalWirelessCommunication, 16=Cx10_05_Basefunction_Infotainment, 0=Cx0_Init}, range raw 0..36028797018963968, transfer-property=TRIGGERED-ON-CHANGE  # FCAB = Funktions-Cluster-Aktiv-Bits
          signal NM_RGS_VL_NM_State_XIX_NM_RGS_VL_XIX_Airbag_SUBCANFD01: start 144, 6 bit, little-endian, data-type-policy=OVERRIDE, i-signal-type=PRIMITIVE, init-value=0, base-type=uint8, implementation-data-type=DT_NM_RGS_VL_NM_State_XIX_NM_RGS_VL_XIX_Airbag_SUBCANFD01, compu {0=Cx0_Init, 32=Cx20_reserved, 2=Cx2_NM_RM_aus_PBSM, 1=Cx1_NM_RM_aus_BSM, 4=Cx4_NM_NO_aus_RM, 8=Cx8_NM_NO_aus_RS, 16=Cx10_reserved}, range raw 0..32, transfer-property=TRIGGERED  # 1 = Zustand Repeat Message (<-- Bus-Sleep Mode) 2 = Zustand Repeat Message (<-- Prepare Bus-Sleep Mode) 4 = Zustand Normal Operation (<-- Repeat Message) 8 = Zustand Normal Operation (<-- Ready Sleep)
          signal NM_RGS_VL_NM_aktiv_Diag_XIX_NM_RGS_VL_XIX_Airbag_SUBCANFD01: start 161, 1 bit, little-endian, data-type-policy=OVERRIDE, i-signal-type=PRIMITIVE, init-value=0, base-type=uint8, implementation-data-type=DT_NM_RGS_VL_NM_aktiv_Diag_XIX_NM_RGS_VL_XIX_Airbag_SUBCANFD01, compu {1=Cx1_Diagnose_aktiv, 0=Cx0_Inaktiv}, range raw 0..1, transfer-property=TRIGGERED  # Diagnose befindet sich nach VW80124 in einer NonDefaultDiagnostic-Session, z.B. ExtendedDiagnostic-Session
          signal NM_RGS_VL_NM_aktiv_KL15_XIX_NM_RGS_VL_XIX_Airbag_SUBCANFD01: start 160, 1 bit, little-endian, data-type-policy=OVERRIDE, i-signal-type=PRIMITIVE, init-value=0, base-type=uint8, implementation-data-type=DT_NM_RGS_VL_NM_aktiv_KL15_XIX_NM_RGS_VL_XIX_Airbag_SUBCANFD01, compu {0=Cx0_Inaktiv, 1=Cx1_KL15_EIN}, range raw 0..1, transfer-property=TRIGGERED  # Steuergerät hat KL15-EIN erkannt
          signal NM_RGS_VL_NM_aktiv_Mot_aktiv_XIX_NM_RGS_VL_XIX_Airbag_SUBCANFD01: start 163, 1 bit, little-endian, data-type-policy=OVERRIDE, i-signal-type=PRIMITIVE, init-value=0, base-type=uint8, implementation-data-type=DT_NM_RGS_VL_NM_aktiv_Mot_aktiv_XIX_NM_RGS_VL_XIX_Airbag_SUBCANFD01, compu {0=Cx0_Inaktiv, 1=Cx1_RGS_Motor_aktiv}, range raw 0..1, transfer-property=TRIGGERED  # Solange RGS Motor aktiv ist wird der SC-CAN wachgehalten
          signal NM_RGS_VL_NM_aktiv_Tmin_XIX_NM_RGS_VL_XIX_Airbag_SUBCANFD01: start 162, 1 bit, little-endian, data-type-policy=OVERRIDE, i-signal-type=PRIMITIVE, init-value=0, base-type=uint8, implementation-data-type=DT_NM_RGS_VL_NM_aktiv_Tmin_XIX_NM_RGS_VL_XIX_Airbag_SUBCANFD01, compu {1=Cx1_Mindestaktivzeit, 0=Cx0_Inaktiv}, range raw 0..1, transfer-property=TRIGGERED  # Mindestaktivzeit ist noch nicht abgelaufen (bei jedem Weckereignis wird die Mindestaktivzeit neu gestartet)
          signal NM_RGS_VL_SNI_10_XIX_NM_RGS_VL_XIX_Airbag_SUBCANFD01: start 128, 10 bit, little-endian, data-type-policy=OVERRIDE, i-signal-type=PRIMITIVE, init-value=94, base-type=uint16, implementation-data-type=DT_NM_RGS_VL_SNI_10_XIX_NM_RGS_VL_XIX_Airbag_SUBCANFD01, compu {94=Cx5e_RGS_VL_SNI}, range raw 94, transfer-property=TRIGGERED  # Source Node-Identifier (SNI) identifiziert den Sender der NM-Botschaft (Knotenadresse) eindeutig im Fahrzeug
          signal NM_RGS_VL_UDS_CC_XIX_NM_RGS_VL_XIX_Airbag_SUBCANFD01: start 151, 1 bit, little-endian, data-type-policy=OVERRIDE, i-signal-type=PRIMITIVE, init-value=0, base-type=uint8, implementation-data-type=DT_NM_RGS_VL_UDS_CC_XIX_NM_RGS_VL_XIX_Airbag_SUBCANFD01, compu {1=Cx1_CC_aktiv, 0=Cx0_Inaktiv}, range raw 0..1, transfer-property=TRIGGERED  # Funktionseinschränkung aufgrund aktivem UDS-Communication Control, siehe VW80124
          signal NM_RGS_VL_Wakeup_XIX_NM_RGS_VL_XIX_Airbag_SUBCANFD01: start 152, 8 bit, little-endian, data-type-policy=OVERRIDE, i-signal-type=PRIMITIVE, init-value=0, base-type=uint8, implementation-data-type=DT_NM_RGS_VL_Wakeup_XIX_NM_RGS_VL_XIX_Airbag_SUBCANFD01, compu {1=Cx1_Bus_Wakeup, 0=Cx0_Peripherie_Wakeup_Ursache_nicht_bekannt, 2=Cx2_KL15_HW}, range raw 0..2, transfer-property=TRIGGERED  # enthält die Weckursache; stehen mehrere Weckursachen parallel an, dann muss der kleinste Wert übertragen werden
      frame RGS_Anf_01_XIX_Airbag_SUBCANFD01: id 0x12DD551D, to RGS_VL, frame-length=16, can-addressing-mode=EXTENDED, can-fd-frame-support=true, can-frame-rx-behavior=CAN-FD, can-frame-tx-behavior=CAN-FD
        pdu RGS_Anf_01_XIX_Airbag_SUBCANFD01: length=16, minimum-delay=0.01, transmission-mode-true-timing={cyclic-timing={time-offset=0.0, time-period=0.5}, event-controlled-timing={number-of-repetitions=5, repetition-period=0.01}}, unused-bit-pattern=0
          signal RGS_HL_Anforderung_XIX_RGS_Anf_01_XIX_Airbag_SUBCANFD01: start 22, 5 bit, little-endian, data-type-policy=OVERRIDE, i-signal-type=PRIMITIVE, init-value=31, base-type=uint8, implementation-data-type=DT_RGS_HL_Anforderung_XIX_RGS_Anf_01_XIX_Airbag_SUBCANFD01, compu {25=Cx19_Loesekurve_1_Loesen_erlaubt (Loesekurve_1 (Loesen_erlaubt)), 13=Cxd_Straffung_13, 7=Cx7_Straffung_7, 9=Cx9_Straffung_9, 27=Cx1b_Funktion_beenden_Abbruch_Abwurf (Funktion_beenden (Abbruch/Abwurf)), 20=Cx14_Gurtparken_1, 24=Cx18_Antipatina, 21=Cx15_Gurtparken_2, 11=Cxb_Straffung_11, 6=Cx6_Straffung_6, 16=Cx10_Straffung_16, 1=Cx1_Straffung_1_maxGurtkraft (Straffung_1 (maxGurtkraft)), 0=Cx0_keine_Aktion, 26=Cx1a_Loesekurve_2, 23=Cx17_Gurtlosereduzierung, 22=Cx16_Crashabschaltung, 4=Cx4_Straffung_4_NGU (Straffung_4 (NGU)), 14=Cxe_Straffung_14, 2=Cx2_Straffung_2, 19=Cx13_Frei, 30=Cx1e_Init, 3=Cx3_Straffung_3, 8=Cx8_Straffung_8, 18=Cx12_Straffung_18, 5=Cx5_Straffung_5, 12=Cxc_Straffung_12, 15=Cxf_Straffung_15, 10=Cxa_Straffung_10, 17=Cx11_Straffung_17_Haptik (Straffung_17 (Haptik))}, range raw 0..30, transfer-property=TRIGGERED-ON-CHANGE  # Ansteuerung Reversibler Gurstraffer_HL
          signal RGS_HL_Nachlauf_2_XIX_RGS_Anf_01_XIX_Airbag_SUBCANFD01: start 34, 1 bit, little-endian, data-type-policy=OVERRIDE, i-signal-type=PRIMITIVE, init-value=0, base-type=uint8, implementation-data-type=DT_RGS_HL_Nachlauf_2_XIX_RGS_Anf_01_XIX_Airbag_SUBCANFD01, compu {1=Cx1_Nachlauf_2_aktiv, 0=Cx0_Nachlauf_2_nicht_aktiv}, range raw 0..1, transfer-property=PENDING  # RGS HL führt die Nachlaufzeit 2 aus
          signal RGS_HR_Anforderung_XIX_RGS_Anf_01_XIX_Airbag_SUBCANFD01: start 27, 5 bit, little-endian, data-type-policy=OVERRIDE, i-signal-type=PRIMITIVE, init-value=31, base-type=uint8, implementation-data-type=DT_RGS_HR_Anforderung_XIX_RGS_Anf_01_XIX_Airbag_SUBCANFD01, compu {6=Cx6_Straffung_6, 12=Cxc_Straffung_12, 11=Cxb_Straffung_11, 14=Cxe_Straffung_14, 17=Cx11_Straffung_17_Haptik (Straffung_17 (Haptik)), 26=Cx1a_Loesekurve_2, 25=Cx19_Loesekurve_1_Loesen_erlaubt (Loesekurve_1 (Loesen_erlaubt)), 16=Cx10_Straffung_16, 18=Cx12_Straffung_18, 7=Cx7_Straffung_7, 0=Cx0_keine_Aktion, 5=Cx5_Straffung_5, 8=Cx8_Straffung_8, 21=Cx15_Gurtparken_2, 10=Cxa_Straffung_10, 20=Cx14_Gurtparken_1, 15=Cxf_Straffung_15, 13=Cxd_Straffung_13, 4=Cx4_Straffung_4_NGU (Straffung_4 (NGU)), 3=Cx3_Straffung_3, 9=Cx9_Straffung_9, 22=Cx16_Crashabschaltung, 24=Cx18_Antipatina, 2=Cx2_Straffung_2, 23=Cx17_Gurtlosereduzierung, 1=Cx1_Straffung_1_maxGurtkraft (Straffung_1 (maxGurtkraft)), 27=Cx1b_Funktion_beenden_Abbruch_Abwurf (Funktion_beenden (Abbruch/Abwurf)), 30=Cx1e_Init, 19=Cx13_Frei}, range raw 0..30, transfer-property=TRIGGERED-ON-CHANGE  # Ansteuerung Reversibler Gurstraffer_VL
          signal RGS_HR_Nachlauf_2_XIX_RGS_Anf_01_XIX_Airbag_SUBCANFD01: start 35, 1 bit, little-endian, data-type-policy=OVERRIDE, i-signal-type=PRIMITIVE, init-value=0, base-type=uint8, implementation-data-type=DT_RGS_HR_Nachlauf_2_XIX_RGS_Anf_01_XIX_Airbag_SUBCANFD01, compu {0=Cx0_Nachlauf_2_nicht_aktiv, 1=Cx1_Nachlauf_2_aktiv}, range raw 0..1, transfer-property=PENDING  # RGS HR führt die Nachlaufzeit 2 aus
          signal RGS_Nachlauf_allg_XIX_RGS_Anf_01_XIX_Airbag_SUBCANFD01: start 36, 1 bit, little-endian, data-type-policy=OVERRIDE, i-signal-type=PRIMITIVE, init-value=0, base-type=uint8, implementation-data-type=DT_RGS_Nachlauf_allg_XIX_RGS_Anf_01_XIX_Airbag_SUBCANFD01, compu {1=Cx1_Nachlauf_aktiv, 0=Cx0_Nachlauf_nicht_aktiv}, range raw 0..1, transfer-property=PENDING, to RGS_VL(timeout 5 s)  # RGS führen Nachlauf aus
          signal RGS_VL_Anforderung_XIX_RGS_Anf_01_XIX_Airbag_SUBCANFD01: start 12, 5 bit, little-endian, data-type-policy=OVERRIDE, i-signal-type=PRIMITIVE, init-value=31, base-type=uint8, implementation-data-type=DT_RGS_VL_Anforderung_XIX_RGS_Anf_01_XIX_Airbag_SUBCANFD01, compu {0=Cx0_keine_Aktion, 18=Cx12_Straffung_18, 27=Cx1b_Funktion_beenden_Abbruch_Abwurf (Funktion_beenden (Abbruch/Abwurf)), 10=Cxa_Straffung_10, 19=Cx13_Frei, 26=Cx1a_Loesekurve_2, 30=Cx1e_Init, 23=Cx17_Gurtlosereduzierung, 13=Cxd_Straffung_13, 1=Cx1_Straffung_1_maxGurtkraft (Straffung_1 (maxGurtkraft)), 25=Cx19_Loesekurve_1_Loesen_erlaubt (Loesekurve_1 (Loesen_erlaubt)), 21=Cx15_Gurtparken_2, 20=Cx14_Gurtparken_1, 2=Cx2_Straffung_2, 8=Cx8_Straffung_8, 15=Cxf_Straffung_15, 9=Cx9_Straffung_9, 5=Cx5_Straffung_5, 6=Cx6_Straffung_6, 11=Cxb_Straffung_11, 22=Cx16_Crashabschaltung, 17=Cx11_Straffung_17_Haptik (Straffung_17 (Haptik)), 24=Cx18_Antipatina, 12=Cxc_Straffung_12, 3=Cx3_Straffung_3, 14=Cxe_Straffung_14, 16=Cx10_Straffung_16, 4=Cx4_Straffung_4_NGU (Straffung_4 (NGU)), 7=Cx7_Straffung_7}, range raw 0..30, transfer-property=TRIGGERED-ON-CHANGE, to RGS_VL(timeout 5 s)  # Ansteuerung Reversibler Gurstraffer_VL
          signal RGS_VL_Nachlauf_2_XIX_RGS_Anf_01_XIX_Airbag_SUBCANFD01: start 32, 1 bit, little-endian, data-type-policy=OVERRIDE, i-signal-type=PRIMITIVE, init-value=0, base-type=uint8, implementation-data-type=DT_RGS_VL_Nachlauf_2_XIX_RGS_Anf_01_XIX_Airbag_SUBCANFD01, compu {0=Cx0_Nachlauf_2_nicht_aktiv, 1=Cx1_Nachlauf_2_aktiv}, range raw 0..1, transfer-property=PENDING, to RGS_VL(timeout 5 s)  # RGS VL führt die Nachlaufzeit 2 aus
          signal RGS_VR_Anforderung_XIX_RGS_Anf_01_XIX_Airbag_SUBCANFD01: start 17, 5 bit, little-endian, data-type-policy=OVERRIDE, i-signal-type=PRIMITIVE, init-value=31, base-type=uint8, implementation-data-type=DT_RGS_VR_Anforderung_XIX_RGS_Anf_01_XIX_Airbag_SUBCANFD01, compu {26=Cx1a_Loesekurve_2, 10=Cxa_Straffung_10, 13=Cxd_Straffung_13, 25=Cx19_Loesekurve_1_Loesen_erlaubt (Loesekurve_1 (Loesen_erlaubt)), 3=Cx3_Straffung_3, 30=Cx1e_Init, 9=Cx9_Straffung_9, 21=Cx15_Gurtparken_2, 18=Cx12_Straffung_18, 5=Cx5_Straffung_5, 27=Cx1b_Funktion_beenden_Abbruch_Abwurf (Funktion_beenden (Abbruch/Abwurf)), 11=Cxb_Straffung_11, 4=Cx4_Straffung_4_NGU (Straffung_4 (NGU)), 17=Cx11_Straffung_17_Haptik (Straffung_17 (Haptik)), 0=Cx0_keine_Aktion, 24=Cx18_Antipatina, 14=Cxe_Straffung_14, 19=Cx13_Frei, 22=Cx16_Crashabschaltung, 16=Cx10_Straffung_16, 20=Cx14_Gurtparken_1, 15=Cxf_Straffung_15, 23=Cx17_Gurtlosereduzierung, 1=Cx1_Straffung_1_maxGurtkraft (Straffung_1 (maxGurtkraft)), 6=Cx6_Straffung_6, 12=Cxc_Straffung_12, 8=Cx8_Straffung_8, 7=Cx7_Straffung_7, 2=Cx2_Straffung_2}, range raw 0..30, transfer-property=TRIGGERED-ON-CHANGE  # Ansteuerung Reversibler Gurstraffer_VR
          signal RGS_VR_Nachlauf_2_XIX_RGS_Anf_01_XIX_Airbag_SUBCANFD01: start 33, 1 bit, little-endian, data-type-policy=OVERRIDE, i-signal-type=PRIMITIVE, init-value=0, base-type=uint8, implementation-data-type=DT_RGS_VR_Nachlauf_2_XIX_RGS_Anf_01_XIX_Airbag_SUBCANFD01, compu {1=Cx1_Nachlauf_2_aktiv, 0=Cx0_Nachlauf_2_nicht_aktiv}, range raw 0..1, transfer-property=PENDING  # RGS VR führt die Nachlaufzeit 2 aus
      frame RGS_VL_01_XIX_Airbag_SUBCANFD01: id 0x3D8, from RGS_VL, frame-length=16, can-addressing-mode=STANDARD, can-fd-frame-support=true, can-frame-rx-behavior=CAN-FD, can-frame-tx-behavior=CAN-FD
        pdu RGS_VL_01_XIX_Airbag_SUBCANFD01: length=16, minimum-delay=0.01, transmission-mode-true-timing={cyclic-timing={time-offset=0.0, time-period=0.5}, event-controlled-timing=number-of-repetitions=0}, unused-bit-pattern=0
          signal RGS_VL_Bauteilfehler_XIX_RGS_VL_01_XIX_Airbag_SUBCANFD01: start 37, 1 bit, little-endian, data-type-policy=OVERRIDE, i-signal-type=PRIMITIVE, init-value=1, base-type=uint8, implementation-data-type=DT_RGS_VL_Bauteilfehler_XIX_RGS_VL_01_XIX_Airbag_SUBCANFD01, compu {1=Cx1_Fehler_nicht_aktiv, 0=Cx0_Fehler_aktiv}, range raw 0..1, transfer-property=PENDING  # RGS VL übermittelt einen Bauteilfehler an den Safety Computer.
          signal RGS_VL_Crashabschaltung_XIX_RGS_VL_01_XIX_Airbag_SUBCANFD01: start 52, 1 bit, little-endian, data-type-policy=OVERRIDE, i-signal-type=PRIMITIVE, init-value=1, base-type=uint8, implementation-data-type=DT_RGS_VL_Crashabschaltung_XIX_RGS_VL_01_XIX_Airbag_SUBCANFD01, compu {1=Cx1_Fehler_nicht_aktiv, 0=Cx0_Fehler_aktiv}, range raw 0..1, transfer-property=PENDING  # RGS VL übermittelt an den Safety Computer, dass RGS aufgrund eines Crashevents den Straffvorgang abgebrochen hat.
          signal RGS_VL_EEPROM_Datensatzfehler_XIX_RGS_VL_01_XIX_Airbag_SUBCANFD01: start 55, 1 bit, little-endian, data-type-policy=OVERRIDE, i-signal-type=PRIMITIVE, init-value=1, base-type=uint8, implementation-data-type=DT_RGS_VL_EEPROM_Datensatzfehler_XIX_RGS_VL_01_XIX_Airbag_SUBCANFD01, compu {0=Cx0_Fehler_aktiv, 1=Cx1_Fehler_nicht_aktiv}, range raw 0..1, transfer-property=PENDING  # RGS VL übermittelt einen Datensatzfehler im EEPROM an den Safety Computer.
          signal RGS_VL_Gurtbandauszug_XIX_RGS_VL_01_XIX_Airbag_SUBCANFD01: start 22, 12 bit, little-endian, data-type-policy=OVERRIDE, i-signal-type=PRIMITIVE, init-value=4094, base-type=uint16, implementation-data-type=DT_RGS_VL_Gurtbandauszug_XIX_RGS_VL_01_XIX_Airbag_SUBCANFD01, invalid-value=Invalid_RGS_VL_Gurtbandauszug_XIX_RGS_VL_01_XIX_Airbag_SUBCANFD01:4095, compu {phys=raw*5-10235 for raw 0..4093, 4095=Cxfff_Fehler, 4094=Cxffe_Init; unit Unit_DegreOfArc}, range phys -10235..10230 Unit_DegreOfArc, raw 0..4095, unit=Unit_DegreOfArc, transfer-property=TRIGGERED-ON-CHANGE-WITHOUT-REPETITION  # Länge des Gurtbandauszugs
          signal RGS_VL_Gurtgeschwindigkeit_XIX_RGS_VL_01_XIX_Airbag_SUBCANFD01: start 12, 10 bit, little-endian, data-type-policy=OVERRIDE, i-signal-type=PRIMITIVE, init-value=511, base-type=uint16, implementation-data-type=DT_RGS_VL_Gurtgeschwindigkeit_XIX_RGS_VL_01_XIX_Airbag_SUBCANFD01, invalid-value=Invalid_RGS_VL_Gurtgeschwindigkeit_XIX_RGS_VL_01_XIX_Airbag_SUBCANFD01:1023, compu {phys=raw*5-2555 for raw 1..1021, 1023=Cx3ff_Fehler, 1022=Cx3fe_Auszuggeschwindigkeit_zu_hoch, 0=Cx0_Einlaufgeschwindigkeit_zu_hoch; unit Unit_DegreOfArcPerSecon}, range phys -2550..2550 Unit_DegreOfArcPerSecon, raw 0..1023, unit=Unit_DegreOfArcPerSecon, transfer-property=TRIGGERED-ON-CHANGE-WITHOUT-REPETITION  # positive Werte: Gurtbandauszug negative Werte: Gurtbandeinlauf
          signal RGS_VL_InPos_XIX_RGS_VL_01_XIX_Airbag_SUBCANFD01: start 56, 1 bit, little-endian, data-type-policy=OVERRIDE, i-signal-type=PRIMITIVE, init-value=0, base-type=uint8, implementation-data-type=DT_RGS_VL_InPos_XIX_RGS_VL_01_XIX_Airbag_SUBCANFD01, compu {1=Cx1_In_Position, 0=Cx0_Out_of_Position}, range raw 0..1, transfer-property=PENDING  # Der RGS setzt dieses Signal wenn der Insasse nach Fahrtbeginn an einen "normale" Position ruhig sitzt (keine Gurtlose mehr vorhanden)
          signal RGS_VL_Kommunikationsfehler_ASG_XIX_RGS_VL_01_XIX_Airbag_SUBCANFD01: start 48, 1 bit, little-endian, data-type-policy=OVERRIDE, i-signal-type=PRIMITIVE, init-value=1, base-type=uint8, implementation-data-type=DT_RGS_VL_Kommunikationsfehler_ASG_XIX_RGS_VL_01_XIX_Airbag_SUBCANFD01, compu {1=Cx1_Fehler_nicht_aktiv, 0=Cx0_Fehler_aktiv}, range raw 0..1, transfer-property=PENDING  # RGS VL übermittelt einen Kommunikationsfehler an den Safety Computer.
          signal RGS_VL_Max_Gurtlosezyklen_XIX_RGS_VL_01_XIX_Airbag_SUBCANFD01: start 39, 1 bit, little-endian, data-type-policy=OVERRIDE, i-signal-type=PRIMITIVE, init-value=1, base-type=uint8, implementation-data-type=DT_RGS_VL_Max_Gurtlosezyklen_XIX_RGS_VL_01_XIX_Airbag_SUBCANFD01, compu {1=Cx1_Fehler_nicht_aktiv, 0=Cx0_Fehler_aktiv}, range raw 0..1, transfer-property=PENDING  # RGS VL übermittelt einen Fehler an den Safety Computer wenn die maximalen Straffzyklen erreicht sind.
          signal RGS_VL_Max_Haptikzyklenfehler_XIX_RGS_VL_01_XIX_Airbag_SUBCANFD01: start 51, 1 bit, little-endian, data-type-policy=OVERRIDE, i-signal-type=PRIMITIVE, init-value=1, base-type=uint8, implementation-data-type=DT_RGS_VL_Max_Haptikzyklenfehler_XIX_RGS_VL_01_XIX_Airbag_SUBCANFD01, compu {1=Cx1_Fehler_nicht_aktiv (Fehler nicht aktiv), 0=Cx0_Fehler_aktiv (Fehler aktiv)}, range raw 0..1, transfer-property=PENDING  # Der RGS übermittelt an den Airbag dass die maximale Strazyklen für Haptik erreicht ist
          signal RGS_VL_Max_Straffzyklenfehler_XIX_RGS_VL_01_XIX_Airbag_SUBCANFD01: start 50, 1 bit, little-endian, data-type-policy=OVERRIDE, i-signal-type=PRIMITIVE, init-value=1, base-type=uint8, implementation-data-type=DT_RGS_VL_Max_Straffzyklenfehler_XIX_RGS_VL_01_XIX_Airbag_SUBCANFD01, compu {0=Cx0_Fehler_aktiv (Fehler aktiv), 1=Cx1_Fehler_nicht_aktiv (Fehler nicht aktiv)}, range raw 0..1, transfer-property=PENDING  # RGS VL übermittelt einen Fehler an den Safety Computer wenn die maximalen Straffzyklen erreicht sind.
          signal RGS_VL_Motorfehler_XIX_RGS_VL_01_XIX_Airbag_SUBCANFD01: start 54, 1 bit, little-endian, data-type-policy=OVERRIDE, i-signal-type=PRIMITIVE, init-value=1, base-type=uint8, implementation-data-type=DT_RGS_VL_Motorfehler_XIX_RGS_VL_01_XIX_Airbag_SUBCANFD01, compu {1=Cx1_Fehler_nicht_aktiv, 0=Cx0_Fehler_aktiv}, range raw 0..1, transfer-property=PENDING  # RGS VL übermittelt einen Motorfehler an den Safety Computer.
          signal RGS_VL_Status_XIX_RGS_VL_01_XIX_Airbag_SUBCANFD01: start 65, 5 bit, little-endian, data-type-policy=OVERRIDE, i-signal-type=PRIMITIVE, init-value=31, base-type=uint8, implementation-data-type=DT_RGS_VL_Status_XIX_RGS_VL_01_XIX_Airbag_SUBCANFD01, compu {2=Cx2_Straffung_2, 15=Cxf_Straffung_15, 29=Cx1d_Fehlerhafte_Straffdurchfuehrung, 14=Cxe_Straffung_14, 20=Cx14_Gurtparken_1, 6=Cx6_Straffung_6, 12=Cxc_Straffung_12, 28=Cx1c_Fehlerhafte_Straffanforderung, 22=Cx16_Crashabschaltung, 21=Cx15_Gurtparken_2, 30=Cx1e_Init, 9=Cx9_Straffung_9, 24=Cx18_Antipatina, 26=Cx1a_Loesekurve_2, 11=Cxb_Straffung_11, 0=Cx0_keine_Aktion, 18=Cx12_Straffung_18, 3=Cx3_Straffung_3, 19=Cx13_Frei, 7=Cx7_Straffung_7, 17=Cx11_Straffung_17_Haptik (Straffung_17 (Haptik)), 10=Cxa_Straffung_10, 5=Cx5_Straffung_5, 13=Cxd_Straffung_13, 8=Cx8_Straffung_8, 1=Cx1_Straffung_1_max_Gurtkraft (Straffung_1 (max Gurtkraft)), 4=Cx4_Straffung_4_NGU (Straffung_4 (NGU)), 23=Cx17_Gurtlosereduzierung, 16=Cx10_Straffung_16, 25=Cx19_Loesekurve_1_Loesen_erlaubt (Loesekurve_1 (Loesen_erlaubt)), 27=Cx1b_Funktion_beenden_Abbruch_Abwurf (Funktion_beenden (Abbruch/Abwurf))}, range raw 0..30, transfer-property=PENDING  # Rückantwort von RGS VL, welche Aktion durchgeführt wird
          signal RGS_VL_Strom_XIX_RGS_VL_01_XIX_Airbag_SUBCANFD01: start 57, 8 bit, little-endian, data-type-policy=OVERRIDE, i-signal-type=PRIMITIVE, init-value=254, base-type=uint8, implementation-data-type=DT_RGS_VL_Strom_XIX_RGS_VL_01_XIX_Airbag_SUBCANFD01, invalid-value=Invalid_RGS_VL_Strom_XIX_RGS_VL_01_XIX_Airbag_SUBCANFD01:255, compu {phys=raw*0.2 for raw 1..253, 255=Cxff_Fehler, 254=Cxfe_Init, 0=Cx0_Inaktiv; unit Unit_Amper}, range phys 0.2..50.6 Unit_Amper, raw 0..255, unit=Unit_Amper, transfer-property=PENDING  # RGS VL übermittelt Stromwert an den Safety Computer.
          signal RGS_VL_Temp_XIX_RGS_VL_01_XIX_Airbag_SUBCANFD01: start 40, 8 bit, little-endian, data-type-policy=OVERRIDE, i-signal-type=PRIMITIVE, init-value=254, base-type=uint8, implementation-data-type=DT_RGS_VL_Temp_XIX_RGS_VL_01_XIX_Airbag_SUBCANFD01, invalid-value=Invalid_RGS_VL_Temp_XIX_RGS_VL_01_XIX_Airbag_SUBCANFD01:255, compu {phys=raw*0.5-40 for raw 0..253, 255=Cxff_Fehler, 254=Cxfe_Init; unit Unit_DegreCelsi}, range phys -40..86.5 Unit_DegreCelsi, raw 0..255, unit=Unit_DegreCelsi, transfer-property=PENDING  # RGS VL übermittelt Temperatur an den Safety Computer.
          signal RGS_VL_Ueberspannung_XIX_RGS_VL_01_XIX_Airbag_SUBCANFD01: start 53, 1 bit, little-endian, data-type-policy=OVERRIDE, i-signal-type=PRIMITIVE, init-value=1, base-type=uint8, implementation-data-type=DT_RGS_VL_Ueberspannung_XIX_RGS_VL_01_XIX_Airbag_SUBCANFD01, compu {1=Cx1_Fehler_nicht_aktiv, 0=Cx0_Fehler_aktiv}, range raw 0..1, transfer-property=PENDING  # RGS hinten links übermittelt Ueberspannungsfehler an den Safety Computer.
          signal RGS_VL_Uebertemperatur_defekt_XIX_RGS_VL_01_XIX_Airbag_SUBCANFD01: start 36, 1 bit, little-endian, data-type-policy=OVERRIDE, i-signal-type=PRIMITIVE, init-value=1, base-type=uint8, implementation-data-type=DT_RGS_VL_Uebertemperatur_defekt_XIX_RGS_VL_01_XIX_Airbag_SUBCANFD01, compu {1=Cx1_Fehler_nicht_aktiv, 0=Cx0_Fehler_aktiv}, range raw 0..1, transfer-property=PENDING  # RGS VL übermittelt an den Safety Computer, dass RGS aufgrund eines Temperaturfehlers defekt ist.
          signal RGS_VL_Unterspannung_XIX_RGS_VL_01_XIX_Airbag_SUBCANFD01: start 49, 1 bit, little-endian, data-type-policy=OVERRIDE, i-signal-type=PRIMITIVE, init-value=1, base-type=uint8, implementation-data-type=DT_RGS_VL_Unterspannung_XIX_RGS_VL_01_XIX_Airbag_SUBCANFD01, compu {0=Cx0_Fehler_aktiv, 1=Cx1_Fehler_nicht_aktiv}, range raw 0..1, transfer-property=PENDING  # RGS VL übermittelt Unterspannungsfehler an den Safety Computer.
          signal RGS_VL_keineStraffungUeberspg_XIX_RGS_VL_01_XIX_Airbag_SUBCANFD01: start 38, 1 bit, little-endian, data-type-policy=OVERRIDE, i-signal-type=PRIMITIVE, init-value=1, base-type=uint8, implementation-data-type=DT_RGS_VL_keineStraffungUeberspg_XIX_RGS_VL_01_XIX_Airbag_SUBCANFD01, compu {0=Cx0_Fehler_aktiv, 1=Cx1_Fehler_nicht_aktiv}, range raw 0..1, transfer-property=PENDING  # RGS hinten links übermittelt an den Safety Computer, dass keine Straffung aufgrund Ueberspannung möglich ist.
          signal RGS_VL_keineStraffungUnterspg_XIX_RGS_VL_01_XIX_Airbag_SUBCANFD01: start 34, 1 bit, little-endian, data-type-policy=OVERRIDE, i-signal-type=PRIMITIVE, init-value=1, base-type=uint8, implementation-data-type=DT_RGS_VL_keineStraffungUnterspg_XIX_RGS_VL_01_XIX_Airbag_SUBCANFD01, compu {1=Cx1_Fehler_nicht_aktiv, 0=Cx0_Fehler_aktiv}, range raw 0..1, transfer-property=PENDING  # RGS VL übermittelt an den Safety Computer, dass keine Straffung aufgrund Unterspannung möglich ist.
          signal RGS_VL_nicht_programmiert_XIX_RGS_VL_01_XIX_Airbag_SUBCANFD01: start 35, 1 bit, little-endian, data-type-policy=OVERRIDE, i-signal-type=PRIMITIVE, init-value=1, base-type=uint8, implementation-data-type=DT_RGS_VL_nicht_programmiert_XIX_RGS_VL_01_XIX_Airbag_SUBCANFD01, compu {0=Cx0_Fehler_aktiv, 1=Cx1_Fehler_nicht_aktiv}, range raw 0..1, transfer-property=PENDING  # RGS VL übermittelt einen Fehler an den Safety Computer wenn keine Straffkurven programmiert sind
      pdu triggering PT_Airbag_SUBCANFD01_XIX_TPCHType_CANHS_Flash_DIA_XIX_402396714_XIX_402527786_XIX_Physical: pdu=DCM_Airbag_SUBCANFD01_XIX_TPCHType_CANHS_Flash_DIA_XIX_402396714_XIX_402527786_XIX_Physical, to RGS_VL
      pdu triggering PT_Airbag_SUBCANFD01_XIX_TPCHType_CANHS_Flash_DIA_XIX_402527786_XIX_402396714_XIX_Physical: pdu=DCM_Airbag_SUBCANFD01_XIX_TPCHType_CANHS_Flash_DIA_XIX_402527786_XIX_402396714_XIX_Physical, from RGS_VL
package /NmConfig
  nm config NmConfig
    can nm cluster NmCluster_Airbag_SUBCANFD01: communication-cluster=Airbag_SUBCANFD01, nm-channel-sleep-master=false, nm-synchronizing-network=false, nm-busload-reduction-active=false, nm-cbv-position=0, nm-immediate-nm-transmissions=0, nm-msg-cycle-time=0.2, nm-network-timeout=1.0, nm-remote-sleep-indication-time=0.5, nm-repeat-message-time=4.0, nm-wait-bus-sleep-time=0.75
      can nm node NmNode_RGS_VL_XIX_Airbag_SUBCANFD01: controller=CT_Airbag_SUBCANFD01, nm-if-ecu=NmEcu_RGS_VL, rx-nm-pdu=NM_Airbag_XIX_Airbag_SUBCANFD01, tx-nm-pdu=NM_RGS_VL_XIX_Airbag_SUBCANFD01, nm-msg-cycle-offset=0.0, nm-msg-reduced-time=0.0
    nm-if-ecus:
      nm ecu NmEcu_RGS_VL: ecu-instance=RGS_VL, nm-bus-synchronization-enabled=false, nm-com-control-enabled=false, nm-node-detection-enabled=false, nm-node-id-enabled=false, nm-user-data-enabled=true
package /PDU
  dcm i pdu DCM_Airbag_SUBCANFD01_XIX_TPCHType_CANHS_Flash_DIA_XIX_402396714_XIX_402527786_XIX_Physical: length=512, diag-pdu-type=DIAG-REQUEST
  dcm i pdu DCM_Airbag_SUBCANFD01_XIX_TPCHType_CANHS_Flash_DIA_XIX_402527786_XIX_402396714_XIX_Physical: length=512, diag-pdu-type=DIAG-RESPONSE
package /IPDUGroup
  4 x i signal i pdu group:
    RGS_VL_XIX_Airbag_SUBCANFD01_Rx: communication-direction=IN, communication-mode=CAN_Receive_All, i-signal-i-pdus=RGS_Anf_01_XIX_Airbag_SUBCANFD01
    RGS_VL_XIX_Airbag_SUBCANFD01_Tx: communication-direction=OUT, communication-mode=CAN_Transmit_All, i-signal-i-pdus=[KN_RGS_VL_XIX_Airbag_SUBCANFD01, RGS_VL_01_XIX_Airbag_SUBCANFD01]
    RGS_VL_XIX_PNC_13_Airbag_Rx: communication-direction=IN, communication-mode=Receive_13_Airbag, i-signal-i-pdus=RGS_Anf_01_XIX_Airbag_SUBCANFD01
    RGS_VL_XIX_PNC_13_Airbag_Tx: communication-direction=OUT, communication-mode=Transmit_13_Airbag, i-signal-i-pdus=RGS_VL_01_XIX_Airbag_SUBCANFD01
package /Unit
  4 x unit:
    Unit_Unit_Amper: display-name=Unit_Amper, factor-si-to-unit=1.0, physical-dimension=PD_siAmpere
    Unit_Unit_DegreCelsi: display-name=Unit_DegreCelsi, factor-si-to-unit=1.0, offset-si-to-unit=-273.2, physical-dimension=PD_siKelvin
    Unit_Unit_DegreOfArc: display-name=Unit_DegreOfArc, factor-si-to-unit=57.3, physical-dimension=PD_siRadiant
    Unit_Unit_DegreOfArcPerSecon: display-name=Unit_DegreOfArcPerSecon, factor-si-to-unit=57.3, physical-dimension=PD_siRadiantPerSecond
package /PhysicalDimension
  4 x physical dimension:
    PD_siAmpere: current-exp=1
    PD_siKelvin: temperature-exp=1
    PD_siRadiant: length-exp=0
    PD_siRadiantPerSecond: length-exp=0, time-exp=-1
package /TPConfig
  can tp config CanTPConfig_Airbag_SUBCANFD01: communication-cluster=Airbag_SUBCANFD01, can-tp-ecu=RGS_VL
    can tp address TA_402396714: tp-address=402396714
    can tp address TA_402527786: tp-address=402527786
    can tp channel TPC_Airbag_SUBCANFD01_XIX_TPCHType_CANHS_Flash_DIA_XIX_402396714_XIX_402527786_XIX_Physical: channel-id=968760377, channel-mode=HALF-DUPLEX-MODE
    can-tp-connection addressing-format=STANDARD, can-tp-channel=TPC_Airbag_SUBCANFD01_XIX_TPCHType_CANHS_Flash_DIA_XIX_402396714_XIX_402527786_XIX_Physical, cancellation=true, data-pdu=DIA_RGS_VL_Req_XIX_Airbag_SUBCANFD01, flow-control-pdu=DIA_RGS_VL_Resp_XIX_Airbag_SUBCANFD01, max-block-size=15, padding-activation=true, receiver=TPN_RGS_VL_XIX_Airbag_SUBCANFD01_XIX_402527786, ta-type=PHYSICAL, timeout-br=0.1, timeout-bs=1.0, timeout-cr=1.0, timeout-cs=0.2, tp-sdu=DCM_Airbag_SUBCANFD01_XIX_TPCHType_CANHS_Flash_DIA_XIX_402396714_XIX_402527786_XIX_Physical, transmitter=TPN_Airbag_6D_XIX_Airbag_SUBCANFD01_XIX_402396714:
      ident TPCN_Airbag_SUBCANFD01_XIX_TPCHType_CANHS_Flash_DIA_XIX_402396714_Airbag_6D_XIX_402527786_RGS_VL_XIX_Physical
    can-tp-connection addressing-format=STANDARD, can-tp-channel=TPC_Airbag_SUBCANFD01_XIX_TPCHType_CANHS_Flash_DIA_XIX_402396714_XIX_402527786_XIX_Physical, cancellation=true, data-pdu=DIA_RGS_VL_Resp_XIX_Airbag_SUBCANFD01, flow-control-pdu=DIA_RGS_VL_Req_XIX_Airbag_SUBCANFD01, max-block-size=15, padding-activation=true, receiver=TPN_Airbag_6D_XIX_Airbag_SUBCANFD01_XIX_402396714, ta-type=PHYSICAL, timeout-br=0.1, timeout-bs=1.0, timeout-cr=1.0, timeout-cs=0.2, tp-sdu=DCM_Airbag_SUBCANFD01_XIX_TPCHType_CANHS_Flash_DIA_XIX_402527786_XIX_402396714_XIX_Physical, transmitter=TPN_RGS_VL_XIX_Airbag_SUBCANFD01_XIX_402527786:
      ident TPCN_Airbag_SUBCANFD01_XIX_TPCHType_CANHS_Flash_DIA_XIX_402527786_RGS_VL_XIX_402396714_Airbag_6D_XIX_Physical
    can tp node TPN_Airbag_6D_XIX_Airbag_SUBCANFD01_XIX_402396714: max-fc-wait=15, st-min=0.005, timeout-ar=1.0, timeout-as=1.0, tp-address=TA_402396714
    can tp node TPN_RGS_VL_XIX_Airbag_SUBCANFD01_XIX_402527786: connector=CN_Airbag_SUBCANFD01, max-fc-wait=15, st-min=0.005, timeout-ar=1.0, timeout-as=1.0, tp-address=TA_402527786
package /Interfaces
  41 x sender receiver interface:
    IF_KN_RGS_VL_BusKnockOut
      data DE_KN_RGS_VL_BusKnockOut: type=DT_KN_RGS_VL_BusKnockOut_XIX_KN_RGS_VL_XIX_Airbag_SUBCANFD01
    IF_KN_RGS_VL_BusKnockOutTimer
      data DE_KN_RGS_VL_BusKnockOutTimer: type=DT_KN_RGS_VL_BusKnockOutTimer_XIX_KN_RGS_VL_XIX_Airbag_SUBCANFD01
    IF_KN_RGS_VL_ECUKnockOut
      data DE_KN_RGS_VL_ECUKnockOut: type=DT_KN_RGS_VL_ECUKnockOut_XIX_KN_RGS_VL_XIX_Airbag_SUBCANFD01
    IF_KN_RGS_VL_ECUKnockOutTimer
      data DE_KN_RGS_VL_ECUKnockOutTimer: type=DT_KN_RGS_VL_ECUKnockOutTimer_XIX_KN_RGS_VL_XIX_Airbag_SUBCANFD01
    IF_NM_Airbag_01_FCAB
      data DE_NM_Airbag_01_FCAB: type=DT_NM_Airbag_01_FCAB_XIX_NM_Airbag_XIX_Airbag_SUBCANFD01
    IF_NM_RGS_VL_CBV_AWB
      data DE_NM_RGS_VL_CBV_AWB: type=DT_NM_RGS_VL_CBV_AWB_XIX_NM_RGS_VL_XIX_Airbag_SUBCANFD01
    IF_NM_RGS_VL_CBV_CRI
      data DE_NM_RGS_VL_CBV_CRI: type=DT_NM_RGS_VL_CBV_CRI_XIX_NM_RGS_VL_XIX_Airbag_SUBCANFD01
    IF_NM_RGS_VL_FCAB
      data DE_NM_RGS_VL_FCAB: type=DT_NM_RGS_VL_FCAB_XIX_NM_RGS_VL_XIX_Airbag_SUBCANFD01
    IF_NM_RGS_VL_FCIB
      data DE_NM_RGS_VL_FCIB: type=DT_NM_RGS_VL_FCIB_XIX_KN_RGS_VL_XIX_Airbag_SUBCANFD01
    IF_NM_RGS_VL_NM_State
      data DE_NM_RGS_VL_NM_State: type=DT_NM_RGS_VL_NM_State_XIX_NM_RGS_VL_XIX_Airbag_SUBCANFD01
    IF_NM_RGS_VL_NM_aktiv_Diag
      data DE_NM_RGS_VL_NM_aktiv_Diag: type=DT_NM_RGS_VL_NM_aktiv_Diag_XIX_NM_RGS_VL_XIX_Airbag_SUBCANFD01
    IF_NM_RGS_VL_NM_aktiv_KL15
      data DE_NM_RGS_VL_NM_aktiv_KL15: type=DT_NM_RGS_VL_NM_aktiv_KL15_XIX_NM_RGS_VL_XIX_Airbag_SUBCANFD01
    IF_NM_RGS_VL_NM_aktiv_Mot_aktiv
      data DE_NM_RGS_VL_NM_aktiv_Mot_aktiv: type=DT_NM_RGS_VL_NM_aktiv_Mot_aktiv_XIX_NM_RGS_VL_XIX_Airbag_SUBCANFD01
    IF_NM_RGS_VL_NM_aktiv_Tmin
      data DE_NM_RGS_VL_NM_aktiv_Tmin: type=DT_NM_RGS_VL_NM_aktiv_Tmin_XIX_NM_RGS_VL_XIX_Airbag_SUBCANFD01
    IF_NM_RGS_VL_SNI_10
      data DE_NM_RGS_VL_SNI_10: type=DT_NM_RGS_VL_SNI_10_XIX_NM_RGS_VL_XIX_Airbag_SUBCANFD01
    IF_NM_RGS_VL_UDS_CC
      data DE_NM_RGS_VL_UDS_CC: type=DT_NM_RGS_VL_UDS_CC_XIX_NM_RGS_VL_XIX_Airbag_SUBCANFD01
    IF_NM_RGS_VL_Wakeup
      data DE_NM_RGS_VL_Wakeup: type=DT_NM_RGS_VL_Wakeup_XIX_NM_RGS_VL_XIX_Airbag_SUBCANFD01
    IF_RGS_Nachlauf_allg
      data DE_RGS_Nachlauf_allg: type=DT_RGS_Nachlauf_allg_XIX_RGS_Anf_01_XIX_Airbag_SUBCANFD01
    IF_RGS_VL_Anforderung
      data DE_RGS_VL_Anforderung: type=DT_RGS_VL_Anforderung_XIX_RGS_Anf_01_XIX_Airbag_SUBCANFD01
    IF_RGS_VL_Bauteilfehler
      data DE_RGS_VL_Bauteilfehler: type=DT_RGS_VL_Bauteilfehler_XIX_RGS_VL_01_XIX_Airbag_SUBCANFD01
    IF_RGS_VL_Crashabschaltung
      data DE_RGS_VL_Crashabschaltung: type=DT_RGS_VL_Crashabschaltung_XIX_RGS_VL_01_XIX_Airbag_SUBCANFD01
    IF_RGS_VL_EEPROM_Datensatzfehler
      data DE_RGS_VL_EEPROM_Datensatzfehler: type=DT_RGS_VL_EEPROM_Datensatzfehler_XIX_RGS_VL_01_XIX_Airbag_SUBCANFD01
    IF_RGS_VL_Gurtbandauszug
      data DE_RGS_VL_Gurtbandauszug: type=DT_RGS_VL_Gurtbandauszug_XIX_RGS_VL_01_XIX_Airbag_SUBCANFD01
    IF_RGS_VL_Gurtgeschwindigkeit
      data DE_RGS_VL_Gurtgeschwindigkeit: type=DT_RGS_VL_Gurtgeschwindigkeit_XIX_RGS_VL_01_XIX_Airbag_SUBCANFD01
    IF_RGS_VL_InPos
      data DE_RGS_VL_InPos: type=DT_RGS_VL_InPos_XIX_RGS_VL_01_XIX_Airbag_SUBCANFD01
    IF_RGS_VL_Kommunikationsfehler_ASG
      data DE_RGS_VL_Kommunikationsfehler_ASG: type=DT_RGS_VL_Kommunikationsfehler_ASG_XIX_RGS_VL_01_XIX_Airbag_SUBCANFD01
    IF_RGS_VL_Max_Gurtlosezyklen
      data DE_RGS_VL_Max_Gurtlosezyklen: type=DT_RGS_VL_Max_Gurtlosezyklen_XIX_RGS_VL_01_XIX_Airbag_SUBCANFD01
    IF_RGS_VL_Max_Haptikzyklenfehler
      data DE_RGS_VL_Max_Haptikzyklenfehler: type=DT_RGS_VL_Max_Haptikzyklenfehler_XIX_RGS_VL_01_XIX_Airbag_SUBCANFD01
    IF_RGS_VL_Max_Straffzyklenfehler
      data DE_RGS_VL_Max_Straffzyklenfehler: type=DT_RGS_VL_Max_Straffzyklenfehler_XIX_RGS_VL_01_XIX_Airbag_SUBCANFD01
    IF_RGS_VL_Motorfehler
      data DE_RGS_VL_Motorfehler: type=DT_RGS_VL_Motorfehler_XIX_RGS_VL_01_XIX_Airbag_SUBCANFD01
    IF_RGS_VL_Nachlauf_2
      data DE_RGS_VL_Nachlauf_2: type=DT_RGS_VL_Nachlauf_2_XIX_RGS_Anf_01_XIX_Airbag_SUBCANFD01
    IF_RGS_VL_Nachlauftyp
      data DE_RGS_VL_Nachlauftyp: type=DT_RGS_VL_Nachlauftyp_XIX_KN_RGS_VL_XIX_Airbag_SUBCANFD01
    IF_RGS_VL_Status
      data DE_RGS_VL_Status: type=DT_RGS_VL_Status_XIX_RGS_VL_01_XIX_Airbag_SUBCANFD01
    IF_RGS_VL_Strom
      data DE_RGS_VL_Strom: type=DT_RGS_VL_Strom_XIX_RGS_VL_01_XIX_Airbag_SUBCANFD01
    IF_RGS_VL_Temp
      data DE_RGS_VL_Temp: type=DT_RGS_VL_Temp_XIX_RGS_VL_01_XIX_Airbag_SUBCANFD01
    IF_RGS_VL_Ueberspannung
      data DE_RGS_VL_Ueberspannung: type=DT_RGS_VL_Ueberspannung_XIX_RGS_VL_01_XIX_Airbag_SUBCANFD01
    IF_RGS_VL_Uebertemperatur_defekt
      data DE_RGS_VL_Uebertemperatur_defekt: type=DT_RGS_VL_Uebertemperatur_defekt_XIX_RGS_VL_01_XIX_Airbag_SUBCANFD01
    IF_RGS_VL_Unterspannung
      data DE_RGS_VL_Unterspannung: type=DT_RGS_VL_Unterspannung_XIX_RGS_VL_01_XIX_Airbag_SUBCANFD01
    IF_RGS_VL_keineStraffungUeberspg
      data DE_RGS_VL_keineStraffungUeberspg: type=DT_RGS_VL_keineStraffungUeberspg_XIX_RGS_VL_01_XIX_Airbag_SUBCANFD01
    IF_RGS_VL_keineStraffungUnterspg
      data DE_RGS_VL_keineStraffungUnterspg: type=DT_RGS_VL_keineStraffungUnterspg_XIX_RGS_VL_01_XIX_Airbag_SUBCANFD01
    IF_RGS_VL_nicht_programmiert
      data DE_RGS_VL_nicht_programmiert: type=DT_RGS_VL_nicht_programmiert_XIX_RGS_VL_01_XIX_Airbag_SUBCANFD01
package /ComponentTypes
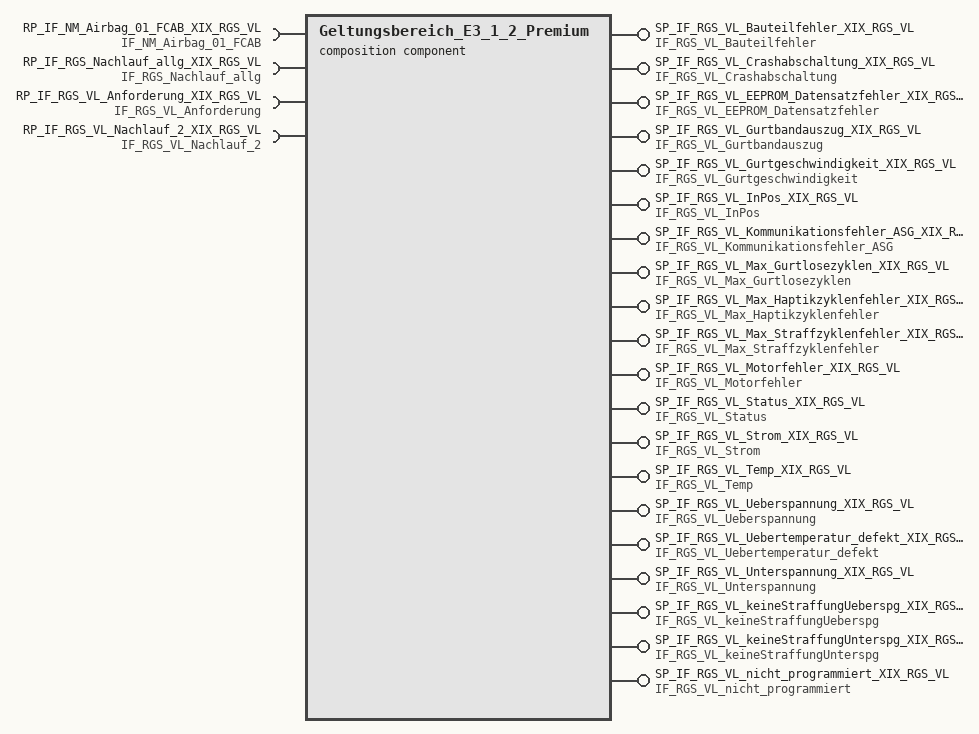
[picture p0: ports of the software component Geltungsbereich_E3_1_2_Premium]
  composition sw component type Geltungsbereich_E3_1_2_Premium
    4 x require port:
      RP_IF_NM_Airbag_01_FCAB_XIX_RGS_VL: required-interface=IF_NM_Airbag_01_FCAB
      RP_IF_RGS_Nachlauf_allg_XIX_RGS_VL: required-interface=IF_RGS_Nachlauf_allg
      RP_IF_RGS_VL_Anforderung_XIX_RGS_VL: required-interface=IF_RGS_VL_Anforderung
      RP_IF_RGS_VL_Nachlauf_2_XIX_RGS_VL: required-interface=IF_RGS_VL_Nachlauf_2
    20 x provide port:
      SP_IF_RGS_VL_Bauteilfehler_XIX_RGS_VL: provided-interface=IF_RGS_VL_Bauteilfehler
      SP_IF_RGS_VL_Crashabschaltung_XIX_RGS_VL: provided-interface=IF_RGS_VL_Crashabschaltung
      SP_IF_RGS_VL_EEPROM_Datensatzfehler_XIX_RGS_VL: provided-interface=IF_RGS_VL_EEPROM_Datensatzfehler
      SP_IF_RGS_VL_Gurtbandauszug_XIX_RGS_VL: provided-interface=IF_RGS_VL_Gurtbandauszug
      SP_IF_RGS_VL_Gurtgeschwindigkeit_XIX_RGS_VL: provided-interface=IF_RGS_VL_Gurtgeschwindigkeit
      SP_IF_RGS_VL_InPos_XIX_RGS_VL: provided-interface=IF_RGS_VL_InPos
      SP_IF_RGS_VL_Kommunikationsfehler_ASG_XIX_RGS_VL: provided-interface=IF_RGS_VL_Kommunikationsfehler_ASG
      SP_IF_RGS_VL_Max_Gurtlosezyklen_XIX_RGS_VL: provided-interface=IF_RGS_VL_Max_Gurtlosezyklen
      SP_IF_RGS_VL_Max_Haptikzyklenfehler_XIX_RGS_VL: provided-interface=IF_RGS_VL_Max_Haptikzyklenfehler
      SP_IF_RGS_VL_Max_Straffzyklenfehler_XIX_RGS_VL: provided-interface=IF_RGS_VL_Max_Straffzyklenfehler
      SP_IF_RGS_VL_Motorfehler_XIX_RGS_VL: provided-interface=IF_RGS_VL_Motorfehler
      SP_IF_RGS_VL_Status_XIX_RGS_VL: provided-interface=IF_RGS_VL_Status
      SP_IF_RGS_VL_Strom_XIX_RGS_VL: provided-interface=IF_RGS_VL_Strom
      SP_IF_RGS_VL_Temp_XIX_RGS_VL: provided-interface=IF_RGS_VL_Temp
      SP_IF_RGS_VL_Ueberspannung_XIX_RGS_VL: provided-interface=IF_RGS_VL_Ueberspannung
      SP_IF_RGS_VL_Uebertemperatur_defekt_XIX_RGS_VL: provided-interface=IF_RGS_VL_Uebertemperatur_defekt
      SP_IF_RGS_VL_Unterspannung_XIX_RGS_VL: provided-interface=IF_RGS_VL_Unterspannung
      SP_IF_RGS_VL_keineStraffungUeberspg_XIX_RGS_VL: provided-interface=IF_RGS_VL_keineStraffungUeberspg
      SP_IF_RGS_VL_keineStraffungUnterspg_XIX_RGS_VL: provided-interface=IF_RGS_VL_keineStraffungUnterspg
      SP_IF_RGS_VL_nicht_programmiert_XIX_RGS_VL: provided-interface=IF_RGS_VL_nicht_programmiert
    component Infrastructure_RGS_VL_XIX_network_infrastructure_XIX_RGS_VL: type=Infrastructure_RGS_VL_XIX_network_infrastructure_XIX_RGS_VL
    component ReversiblenGurtStraffen_VL_XIX_Gurtfunktionen_XIX_RGS_VL: type=ReversiblenGurtStraffen_VL_XIX_Gurtfunktionen_XIX_RGS_VL
    delegate ReversiblenGurtStraffen_VL_XIX_Gurtfunktionen_XIX_RGS_VL.RP_IF_RGS_VL_Nachlauf_2_XIX_ReversiblenGurtStraffen_VL_XIX_Gurtfunktionen_XIX_RGS_VL <-> outer port RP_IF_RGS_VL_Nachlauf_2_XIX_RGS_VL  # _XIX_BeltRetractorControl_XIX_Gurtfunktionen_XIX_Airbag_6D_XIX_ReversiblenGurtStraffen_VL_XIX_Gurtfunktionen_XIX_RGS_VL_XIX_RGS_VL_Nachlauf_2
    delegate ReversiblenGurtStraffen_VL_XIX_Gurtfunktionen_XIX_RGS_VL.RP_IF_RGS_VL_Anforderung_XIX_ReversiblenGurtStraffen_VL_XIX_Gurtfunktionen_XIX_RGS_VL <-> outer port RP_IF_RGS_VL_Anforderung_XIX_RGS_VL  # _XIX_BeltRetractorControl_XIX_Gurtfunktionen_XIX_Airbag_6D_XIX_ReversiblenGurtStraffen_VL_XIX_Gurtfunktionen_XIX_RGS_VL_XIX_RGS_VL_Anforderung
    delegate ReversiblenGurtStraffen_VL_XIX_Gurtfunktionen_XIX_RGS_VL.RP_IF_RGS_Nachlauf_allg_XIX_ReversiblenGurtStraffen_VL_XIX_Gurtfunktionen_XIX_RGS_VL <-> outer port RP_IF_RGS_Nachlauf_allg_XIX_RGS_VL  # _XIX_BeltRetractorControl_XIX_Gurtfunktionen_XIX_Airbag_6D_XIX_ReversiblenGurtStraffen_VL_XIX_Gurtfunktionen_XIX_RGS_VL_XIX_RGS_Nachlauf_allg
    delegate Infrastructure_RGS_VL_XIX_network_infrastructure_XIX_RGS_VL.RP_IF_NM_Airbag_01_FCAB_XIX_Infrastructure_RGS_VL_XIX_network_infrastructure_XIX_RGS_VL <-> outer port RP_IF_NM_Airbag_01_FCAB_XIX_RGS_VL  # _XIX_Infrastructure_Airbag_6D_XIX_network_infrastructure_XIX_Airbag_6D_XIX_Infrastructure_RGS_VL_XIX_network_infrastructure_XIX_RGS_VL_XIX_NM_Airbag_01_FCAB
    delegate ReversiblenGurtStraffen_VL_XIX_Gurtfunktionen_XIX_RGS_VL.SP_IF_RGS_VL_Crashabschaltung_XIX_ReversiblenGurtStraffen_VL_XIX_Gurtfunktionen_XIX_RGS_VL <-> outer port SP_IF_RGS_VL_Crashabschaltung_XIX_RGS_VL  # _XIX_ReversiblenGurtStraffen_VL_XIX_Gurtfunktionen_XIX_RGS_VL_XIX_BeltRetractorControl_XIX_Gurtfunktionen_XIX_Airbag_6D_XIX_RGS_VL_Crashabschaltung
    delegate ReversiblenGurtStraffen_VL_XIX_Gurtfunktionen_XIX_RGS_VL.SP_IF_RGS_VL_Status_XIX_ReversiblenGurtStraffen_VL_XIX_Gurtfunktionen_XIX_RGS_VL <-> outer port SP_IF_RGS_VL_Status_XIX_RGS_VL  # _XIX_ReversiblenGurtStraffen_VL_XIX_Gurtfunktionen_XIX_RGS_VL_XIX_BeltRetractorControl_XIX_Gurtfunktionen_XIX_Airbag_6D_XIX_RGS_VL_Status
    delegate ReversiblenGurtStraffen_VL_XIX_Gurtfunktionen_XIX_RGS_VL.SP_IF_RGS_VL_Bauteilfehler_XIX_ReversiblenGurtStraffen_VL_XIX_Gurtfunktionen_XIX_RGS_VL <-> outer port SP_IF_RGS_VL_Bauteilfehler_XIX_RGS_VL  # _XIX_ReversiblenGurtStraffen_VL_XIX_Gurtfunktionen_XIX_RGS_VL_XIX_BeltRetractorControl_XIX_Gurtfunktionen_XIX_Airbag_6D_XIX_RGS_VL_Bauteilfehler
    delegate ReversiblenGurtStraffen_VL_XIX_Gurtfunktionen_XIX_RGS_VL.SP_IF_RGS_VL_InPos_XIX_ReversiblenGurtStraffen_VL_XIX_Gurtfunktionen_XIX_RGS_VL <-> outer port SP_IF_RGS_VL_InPos_XIX_RGS_VL  # _XIX_ReversiblenGurtStraffen_VL_XIX_Gurtfunktionen_XIX_RGS_VL_XIX_BeltRetractorControl_XIX_Gurtfunktionen_XIX_Airbag_6D_XIX_RGS_VL_InPos
    delegate ReversiblenGurtStraffen_VL_XIX_Gurtfunktionen_XIX_RGS_VL.SP_IF_RGS_VL_Gurtbandauszug_XIX_ReversiblenGurtStraffen_VL_XIX_Gurtfunktionen_XIX_RGS_VL <-> outer port SP_IF_RGS_VL_Gurtbandauszug_XIX_RGS_VL  # _XIX_ReversiblenGurtStraffen_VL_XIX_Gurtfunktionen_XIX_RGS_VL_XIX_BeltRetractorControl_XIX_Gurtfunktionen_XIX_Airbag_6D_XIX_RGS_VL_Gurtbandauszug
    delegate ReversiblenGurtStraffen_VL_XIX_Gurtfunktionen_XIX_RGS_VL.SP_IF_RGS_VL_Max_Gurtlosezyklen_XIX_ReversiblenGurtStraffen_VL_XIX_Gurtfunktionen_XIX_RGS_VL <-> outer port SP_IF_RGS_VL_Max_Gurtlosezyklen_XIX_RGS_VL  # _XIX_ReversiblenGurtStraffen_VL_XIX_Gurtfunktionen_XIX_RGS_VL_XIX_BeltRetractorControl_XIX_Gurtfunktionen_XIX_Airbag_6D_XIX_RGS_VL_Max_Gurtlosezyklen
    delegate ReversiblenGurtStraffen_VL_XIX_Gurtfunktionen_XIX_RGS_VL.SP_IF_RGS_VL_Unterspannung_XIX_ReversiblenGurtStraffen_VL_XIX_Gurtfunktionen_XIX_RGS_VL <-> outer port SP_IF_RGS_VL_Unterspannung_XIX_RGS_VL  # _XIX_ReversiblenGurtStraffen_VL_XIX_Gurtfunktionen_XIX_RGS_VL_XIX_BeltRetractorControl_XIX_Gurtfunktionen_XIX_Airbag_6D_XIX_RGS_VL_Unterspannung
    delegate ReversiblenGurtStraffen_VL_XIX_Gurtfunktionen_XIX_RGS_VL.SP_IF_RGS_VL_Temp_XIX_ReversiblenGurtStraffen_VL_XIX_Gurtfunktionen_XIX_RGS_VL <-> outer port SP_IF_RGS_VL_Temp_XIX_RGS_VL  # _XIX_ReversiblenGurtStraffen_VL_XIX_Gurtfunktionen_XIX_RGS_VL_XIX_BeltRetractorControl_XIX_Gurtfunktionen_XIX_Airbag_6D_XIX_RGS_VL_Temp
    delegate ReversiblenGurtStraffen_VL_XIX_Gurtfunktionen_XIX_RGS_VL.SP_IF_RGS_VL_Gurtgeschwindigkeit_XIX_ReversiblenGurtStraffen_VL_XIX_Gurtfunktionen_XIX_RGS_VL <-> outer port SP_IF_RGS_VL_Gurtgeschwindigkeit_XIX_RGS_VL  # _XIX_ReversiblenGurtStraffen_VL_XIX_Gurtfunktionen_XIX_RGS_VL_XIX_BeltRetractorControl_XIX_Gurtfunktionen_XIX_Airbag_6D_XIX_RGS_VL_Gurtgeschwindigkeit
    delegate ReversiblenGurtStraffen_VL_XIX_Gurtfunktionen_XIX_RGS_VL.SP_IF_RGS_VL_Motorfehler_XIX_ReversiblenGurtStraffen_VL_XIX_Gurtfunktionen_XIX_RGS_VL <-> outer port SP_IF_RGS_VL_Motorfehler_XIX_RGS_VL  # _XIX_ReversiblenGurtStraffen_VL_XIX_Gurtfunktionen_XIX_RGS_VL_XIX_BeltRetractorControl_XIX_Gurtfunktionen_XIX_Airbag_6D_XIX_RGS_VL_Motorfehler
    delegate ReversiblenGurtStraffen_VL_XIX_Gurtfunktionen_XIX_RGS_VL.SP_IF_RGS_VL_EEPROM_Datensatzfehler_XIX_ReversiblenGurtStraffen_VL_XIX_Gurtfunktionen_XIX_RGS_VL <-> outer port SP_IF_RGS_VL_EEPROM_Datensatzfehler_XIX_RGS_VL  # _XIX_ReversiblenGurtStraffen_VL_XIX_Gurtfunktionen_XIX_RGS_VL_XIX_BeltRetractorControl_XIX_Gurtfunktionen_XIX_Airbag_6D_XIX_RGS_VL_EEPROM_Datensatzfehler
    delegate ReversiblenGurtStraffen_VL_XIX_Gurtfunktionen_XIX_RGS_VL.SP_IF_RGS_VL_Ueberspannung_XIX_ReversiblenGurtStraffen_VL_XIX_Gurtfunktionen_XIX_RGS_VL <-> outer port SP_IF_RGS_VL_Ueberspannung_XIX_RGS_VL  # _XIX_ReversiblenGurtStraffen_VL_XIX_Gurtfunktionen_XIX_RGS_VL_XIX_BeltRetractorControl_XIX_Gurtfunktionen_XIX_Airbag_6D_XIX_RGS_VL_Ueberspannung
    delegate ReversiblenGurtStraffen_VL_XIX_Gurtfunktionen_XIX_RGS_VL.SP_IF_RGS_VL_keineStraffungUnterspg_XIX_ReversiblenGurtStraffen_VL_XIX_Gurtfunktionen_XIX_RGS_VL <-> outer port SP_IF_RGS_VL_keineStraffungUnterspg_XIX_RGS_VL  # _XIX_ReversiblenGurtStraffen_VL_XIX_Gurtfunktionen_XIX_RGS_VL_XIX_BeltRetractorControl_XIX_Gurtfunktionen_XIX_Airbag_6D_XIX_RGS_VL_keineStraffungUnterspg
    delegate ReversiblenGurtStraffen_VL_XIX_Gurtfunktionen_XIX_RGS_VL.SP_IF_RGS_VL_Strom_XIX_ReversiblenGurtStraffen_VL_XIX_Gurtfunktionen_XIX_RGS_VL <-> outer port SP_IF_RGS_VL_Strom_XIX_RGS_VL  # _XIX_ReversiblenGurtStraffen_VL_XIX_Gurtfunktionen_XIX_RGS_VL_XIX_BeltRetractorControl_XIX_Gurtfunktionen_XIX_Airbag_6D_XIX_RGS_VL_Strom
    delegate ReversiblenGurtStraffen_VL_XIX_Gurtfunktionen_XIX_RGS_VL.SP_IF_RGS_VL_Kommunikationsfehler_ASG_XIX_ReversiblenGurtStraffen_VL_XIX_Gurtfunktionen_XIX_RGS_VL <-> outer port SP_IF_RGS_VL_Kommunikationsfehler_ASG_XIX_RGS_VL  # _XIX_ReversiblenGurtStraffen_VL_XIX_Gurtfunktionen_XIX_RGS_VL_XIX_BeltRetractorControl_XIX_Gurtfunktionen_XIX_Airbag_6D_XIX_RGS_VL_Kommunikationsfehler_ASG
    delegate ReversiblenGurtStraffen_VL_XIX_Gurtfunktionen_XIX_RGS_VL.SP_IF_RGS_VL_nicht_programmiert_XIX_ReversiblenGurtStraffen_VL_XIX_Gurtfunktionen_XIX_RGS_VL <-> outer port SP_IF_RGS_VL_nicht_programmiert_XIX_RGS_VL  # _XIX_ReversiblenGurtStraffen_VL_XIX_Gurtfunktionen_XIX_RGS_VL_XIX_BeltRetractorControl_XIX_Gurtfunktionen_XIX_Airbag_6D_XIX_RGS_VL_nicht_programmiert
    delegate ReversiblenGurtStraffen_VL_XIX_Gurtfunktionen_XIX_RGS_VL.SP_IF_RGS_VL_Max_Straffzyklenfehler_XIX_ReversiblenGurtStraffen_VL_XIX_Gurtfunktionen_XIX_RGS_VL <-> outer port SP_IF_RGS_VL_Max_Straffzyklenfehler_XIX_RGS_VL  # _XIX_ReversiblenGurtStraffen_VL_XIX_Gurtfunktionen_XIX_RGS_VL_XIX_BeltRetractorControl_XIX_Gurtfunktionen_XIX_Airbag_6D_XIX_RGS_VL_Max_Straffzyklenfehler
    delegate ReversiblenGurtStraffen_VL_XIX_Gurtfunktionen_XIX_RGS_VL.SP_IF_RGS_VL_keineStraffungUeberspg_XIX_ReversiblenGurtStraffen_VL_XIX_Gurtfunktionen_XIX_RGS_VL <-> outer port SP_IF_RGS_VL_keineStraffungUeberspg_XIX_RGS_VL  # _XIX_ReversiblenGurtStraffen_VL_XIX_Gurtfunktionen_XIX_RGS_VL_XIX_BeltRetractorControl_XIX_Gurtfunktionen_XIX_Airbag_6D_XIX_RGS_VL_keineStraffungUeberspg
    delegate ReversiblenGurtStraffen_VL_XIX_Gurtfunktionen_XIX_RGS_VL.SP_IF_RGS_VL_Max_Haptikzyklenfehler_XIX_ReversiblenGurtStraffen_VL_XIX_Gurtfunktionen_XIX_RGS_VL <-> outer port SP_IF_RGS_VL_Max_Haptikzyklenfehler_XIX_RGS_VL  # _XIX_ReversiblenGurtStraffen_VL_XIX_Gurtfunktionen_XIX_RGS_VL_XIX_BeltRetractorControl_XIX_Gurtfunktionen_XIX_Airbag_6D_XIX_RGS_VL_Max_Haptikzyklenfehler
    delegate ReversiblenGurtStraffen_VL_XIX_Gurtfunktionen_XIX_RGS_VL.SP_IF_RGS_VL_Uebertemperatur_defekt_XIX_ReversiblenGurtStraffen_VL_XIX_Gurtfunktionen_XIX_RGS_VL <-> outer port SP_IF_RGS_VL_Uebertemperatur_defekt_XIX_RGS_VL  # _XIX_ReversiblenGurtStraffen_VL_XIX_Gurtfunktionen_XIX_RGS_VL_XIX_BeltRetractorControl_XIX_Gurtfunktionen_XIX_Airbag_6D_XIX_RGS_VL_Uebertemperatur_defekt
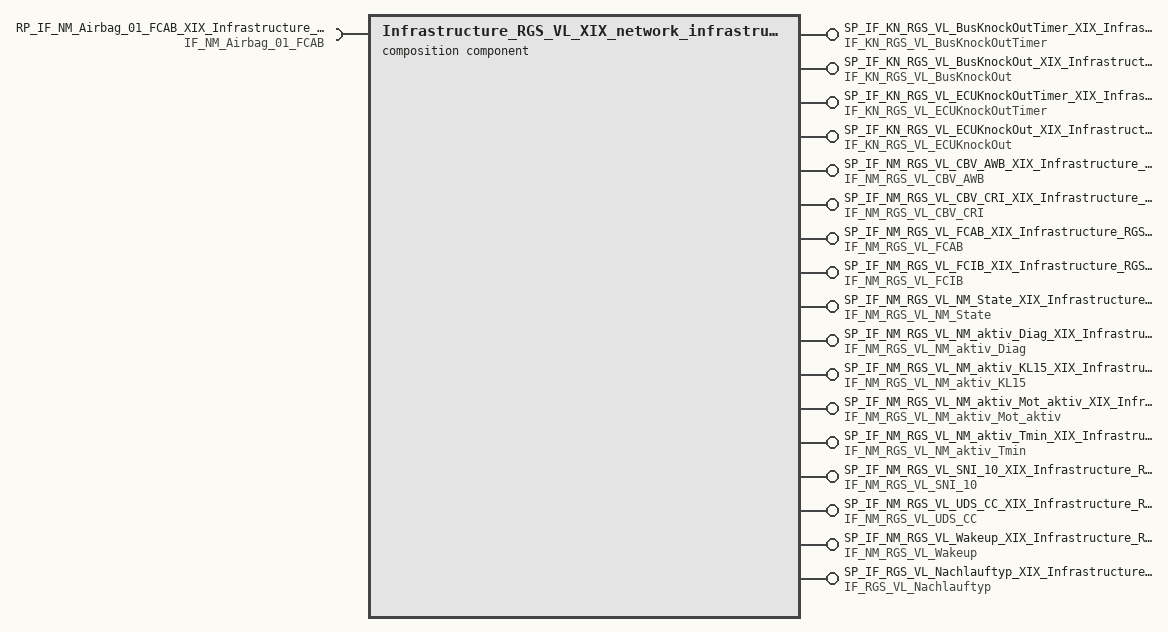
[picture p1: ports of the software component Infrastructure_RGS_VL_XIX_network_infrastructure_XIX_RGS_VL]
  composition sw component type Infrastructure_RGS_VL_XIX_network_infrastructure_XIX_RGS_VL
    require port RP_IF_NM_Airbag_01_FCAB_XIX_Infrastructure_RGS_VL_XIX_network_infrastructure_XIX_RGS_VL: required-interface=IF_NM_Airbag_01_FCAB
    17 x provide port:
      SP_IF_KN_RGS_VL_BusKnockOutTimer_XIX_Infrastructure_RGS_VL_XIX_network_infrastructure_XIX_RGS_VL: provided-interface=IF_KN_RGS_VL_BusKnockOutTimer
      SP_IF_KN_RGS_VL_BusKnockOut_XIX_Infrastructure_RGS_VL_XIX_network_infrastructure_XIX_RGS_VL: provided-interface=IF_KN_RGS_VL_BusKnockOut
      SP_IF_KN_RGS_VL_ECUKnockOutTimer_XIX_Infrastructure_RGS_VL_XIX_network_infrastructure_XIX_RGS_VL: provided-interface=IF_KN_RGS_VL_ECUKnockOutTimer
      SP_IF_KN_RGS_VL_ECUKnockOut_XIX_Infrastructure_RGS_VL_XIX_network_infrastructure_XIX_RGS_VL: provided-interface=IF_KN_RGS_VL_ECUKnockOut
      SP_IF_NM_RGS_VL_CBV_AWB_XIX_Infrastructure_RGS_VL_XIX_network_infrastructure_XIX_RGS_VL: provided-interface=IF_NM_RGS_VL_CBV_AWB
      SP_IF_NM_RGS_VL_CBV_CRI_XIX_Infrastructure_RGS_VL_XIX_network_infrastructure_XIX_RGS_VL: provided-interface=IF_NM_RGS_VL_CBV_CRI
      SP_IF_NM_RGS_VL_FCAB_XIX_Infrastructure_RGS_VL_XIX_network_infrastructure_XIX_RGS_VL: provided-interface=IF_NM_RGS_VL_FCAB
      SP_IF_NM_RGS_VL_FCIB_XIX_Infrastructure_RGS_VL_XIX_network_infrastructure_XIX_RGS_VL: provided-interface=IF_NM_RGS_VL_FCIB
      SP_IF_NM_RGS_VL_NM_State_XIX_Infrastructure_RGS_VL_XIX_network_infrastructure_XIX_RGS_VL: provided-interface=IF_NM_RGS_VL_NM_State
      SP_IF_NM_RGS_VL_NM_aktiv_Diag_XIX_Infrastructure_RGS_VL_XIX_network_infrastructure_XIX_RGS_VL: provided-interface=IF_NM_RGS_VL_NM_aktiv_Diag
      SP_IF_NM_RGS_VL_NM_aktiv_KL15_XIX_Infrastructure_RGS_VL_XIX_network_infrastructure_XIX_RGS_VL: provided-interface=IF_NM_RGS_VL_NM_aktiv_KL15
      SP_IF_NM_RGS_VL_NM_aktiv_Mot_aktiv_XIX_Infrastructure_RGS_VL_XIX_network_infrastructure_XIX_RGS_VL: provided-interface=IF_NM_RGS_VL_NM_aktiv_Mot_aktiv
      SP_IF_NM_RGS_VL_NM_aktiv_Tmin_XIX_Infrastructure_RGS_VL_XIX_network_infrastructure_XIX_RGS_VL: provided-interface=IF_NM_RGS_VL_NM_aktiv_Tmin
      SP_IF_NM_RGS_VL_SNI_10_XIX_Infrastructure_RGS_VL_XIX_network_infrastructure_XIX_RGS_VL: provided-interface=IF_NM_RGS_VL_SNI_10
      SP_IF_NM_RGS_VL_UDS_CC_XIX_Infrastructure_RGS_VL_XIX_network_infrastructure_XIX_RGS_VL: provided-interface=IF_NM_RGS_VL_UDS_CC
      SP_IF_NM_RGS_VL_Wakeup_XIX_Infrastructure_RGS_VL_XIX_network_infrastructure_XIX_RGS_VL: provided-interface=IF_NM_RGS_VL_Wakeup
      SP_IF_RGS_VL_Nachlauftyp_XIX_Infrastructure_RGS_VL_XIX_network_infrastructure_XIX_RGS_VL: provided-interface=IF_RGS_VL_Nachlauftyp
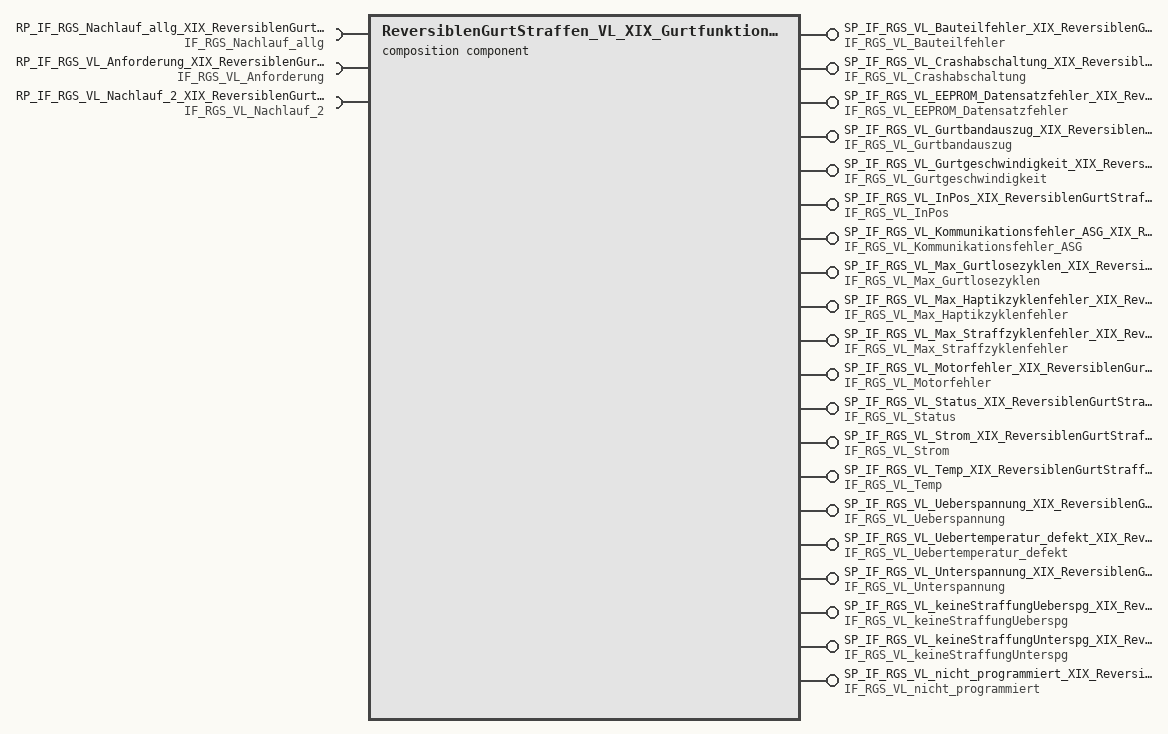
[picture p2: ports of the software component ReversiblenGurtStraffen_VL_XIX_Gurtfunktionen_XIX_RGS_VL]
  composition sw component type ReversiblenGurtStraffen_VL_XIX_Gurtfunktionen_XIX_RGS_VL
    require port RP_IF_RGS_Nachlauf_allg_XIX_ReversiblenGurtStraffen_VL_XIX_Gurtfunktionen_XIX_RGS_VL: required-interface=IF_RGS_Nachlauf_allg
    require port RP_IF_RGS_VL_Anforderung_XIX_ReversiblenGurtStraffen_VL_XIX_Gurtfunktionen_XIX_RGS_VL: required-interface=IF_RGS_VL_Anforderung
    require port RP_IF_RGS_VL_Nachlauf_2_XIX_ReversiblenGurtStraffen_VL_XIX_Gurtfunktionen_XIX_RGS_VL: required-interface=IF_RGS_VL_Nachlauf_2
    20 x provide port:
      SP_IF_RGS_VL_Bauteilfehler_XIX_ReversiblenGurtStraffen_VL_XIX_Gurtfunktionen_XIX_RGS_VL: provided-interface=IF_RGS_VL_Bauteilfehler
      SP_IF_RGS_VL_Crashabschaltung_XIX_ReversiblenGurtStraffen_VL_XIX_Gurtfunktionen_XIX_RGS_VL: provided-interface=IF_RGS_VL_Crashabschaltung
      SP_IF_RGS_VL_EEPROM_Datensatzfehler_XIX_ReversiblenGurtStraffen_VL_XIX_Gurtfunktionen_XIX_RGS_VL: provided-interface=IF_RGS_VL_EEPROM_Datensatzfehler
      SP_IF_RGS_VL_Gurtbandauszug_XIX_ReversiblenGurtStraffen_VL_XIX_Gurtfunktionen_XIX_RGS_VL: provided-interface=IF_RGS_VL_Gurtbandauszug
      SP_IF_RGS_VL_Gurtgeschwindigkeit_XIX_ReversiblenGurtStraffen_VL_XIX_Gurtfunktionen_XIX_RGS_VL: provided-interface=IF_RGS_VL_Gurtgeschwindigkeit
      SP_IF_RGS_VL_InPos_XIX_ReversiblenGurtStraffen_VL_XIX_Gurtfunktionen_XIX_RGS_VL: provided-interface=IF_RGS_VL_InPos
      SP_IF_RGS_VL_Kommunikationsfehler_ASG_XIX_ReversiblenGurtStraffen_VL_XIX_Gurtfunktionen_XIX_RGS_VL: provided-interface=IF_RGS_VL_Kommunikationsfehler_ASG
      SP_IF_RGS_VL_Max_Gurtlosezyklen_XIX_ReversiblenGurtStraffen_VL_XIX_Gurtfunktionen_XIX_RGS_VL: provided-interface=IF_RGS_VL_Max_Gurtlosezyklen
      SP_IF_RGS_VL_Max_Haptikzyklenfehler_XIX_ReversiblenGurtStraffen_VL_XIX_Gurtfunktionen_XIX_RGS_VL: provided-interface=IF_RGS_VL_Max_Haptikzyklenfehler
      SP_IF_RGS_VL_Max_Straffzyklenfehler_XIX_ReversiblenGurtStraffen_VL_XIX_Gurtfunktionen_XIX_RGS_VL: provided-interface=IF_RGS_VL_Max_Straffzyklenfehler
      SP_IF_RGS_VL_Motorfehler_XIX_ReversiblenGurtStraffen_VL_XIX_Gurtfunktionen_XIX_RGS_VL: provided-interface=IF_RGS_VL_Motorfehler
      SP_IF_RGS_VL_Status_XIX_ReversiblenGurtStraffen_VL_XIX_Gurtfunktionen_XIX_RGS_VL: provided-interface=IF_RGS_VL_Status
      SP_IF_RGS_VL_Strom_XIX_ReversiblenGurtStraffen_VL_XIX_Gurtfunktionen_XIX_RGS_VL: provided-interface=IF_RGS_VL_Strom
      SP_IF_RGS_VL_Temp_XIX_ReversiblenGurtStraffen_VL_XIX_Gurtfunktionen_XIX_RGS_VL: provided-interface=IF_RGS_VL_Temp
      SP_IF_RGS_VL_Ueberspannung_XIX_ReversiblenGurtStraffen_VL_XIX_Gurtfunktionen_XIX_RGS_VL: provided-interface=IF_RGS_VL_Ueberspannung
      SP_IF_RGS_VL_Uebertemperatur_defekt_XIX_ReversiblenGurtStraffen_VL_XIX_Gurtfunktionen_XIX_RGS_VL: provided-interface=IF_RGS_VL_Uebertemperatur_defekt
      SP_IF_RGS_VL_Unterspannung_XIX_ReversiblenGurtStraffen_VL_XIX_Gurtfunktionen_XIX_RGS_VL: provided-interface=IF_RGS_VL_Unterspannung
      SP_IF_RGS_VL_keineStraffungUeberspg_XIX_ReversiblenGurtStraffen_VL_XIX_Gurtfunktionen_XIX_RGS_VL: provided-interface=IF_RGS_VL_keineStraffungUeberspg
      SP_IF_RGS_VL_keineStraffungUnterspg_XIX_ReversiblenGurtStraffen_VL_XIX_Gurtfunktionen_XIX_RGS_VL: provided-interface=IF_RGS_VL_keineStraffungUnterspg
      SP_IF_RGS_VL_nicht_programmiert_XIX_ReversiblenGurtStraffen_VL_XIX_Gurtfunktionen_XIX_RGS_VL: provided-interface=IF_RGS_VL_nicht_programmiert
package /ImplementationDataTypes
  67 x impl type:
    DT_KN_RGS_VL_BusKnockOutTimer_XIX_KN_RGS_VL_XIX_Airbag_SUBCANFD01: implementation-data-type=uint8
    DT_KN_RGS_VL_BusKnockOut_XIX_KN_RGS_VL_XIX_Airbag_SUBCANFD01: implementation-data-type=uint8
    DT_KN_RGS_VL_ECUKnockOutTimer_XIX_KN_RGS_VL_XIX_Airbag_SUBCANFD01: implementation-data-type=uint8
    DT_KN_RGS_VL_ECUKnockOut_XIX_KN_RGS_VL_XIX_Airbag_SUBCANFD01: implementation-data-type=uint8
    DT_NM_Airbag_01_CBV_AWB_XIX_NM_Airbag_XIX_Airbag_SUBCANFD01: implementation-data-type=uint8
    DT_NM_Airbag_01_CBV_CRI_XIX_NM_Airbag_XIX_Airbag_SUBCANFD01: implementation-data-type=uint8
    DT_NM_Airbag_01_FCAB_XIX_NM_Airbag_XIX_Airbag_SUBCANFD01: category=ARRAY
      element ARRAY_ELEMENT: array-size=7, array-size-semantics=FIXED-SIZE, implementation-data-type=uint8
    DT_NM_Airbag_01_NM_State_XIX_NM_Airbag_XIX_Airbag_SUBCANFD01: implementation-data-type=uint8
    DT_NM_Airbag_01_NM_aktiv_Diag_XIX_NM_Airbag_XIX_Airbag_SUBCANFD01: implementation-data-type=uint8
    DT_NM_Airbag_01_NM_aktiv_KL15_XIX_NM_Airbag_XIX_Airbag_SUBCANFD01: implementation-data-type=uint8
    DT_NM_Airbag_01_NM_aktiv_Tmin_XIX_NM_Airbag_XIX_Airbag_SUBCANFD01: implementation-data-type=uint8
    DT_NM_Airbag_01_SNI_10_XIX_NM_Airbag_XIX_Airbag_SUBCANFD01: implementation-data-type=uint16
    DT_NM_Airbag_01_UDS_CC_XIX_NM_Airbag_XIX_Airbag_SUBCANFD01: implementation-data-type=uint8
    DT_NM_Airbag_01_Wakeup_XIX_NM_Airbag_XIX_Airbag_SUBCANFD01: implementation-data-type=uint8
    DT_NM_RGS_VL_CBV_AWB_XIX_NM_RGS_VL_XIX_Airbag_SUBCANFD01: implementation-data-type=uint8
    DT_NM_RGS_VL_CBV_CRI_XIX_NM_RGS_VL_XIX_Airbag_SUBCANFD01: implementation-data-type=uint8
    DT_NM_RGS_VL_FCAB_XIX_NM_RGS_VL_XIX_Airbag_SUBCANFD01: category=ARRAY
      element ARRAY_ELEMENT: array-size=7, array-size-semantics=FIXED-SIZE, implementation-data-type=uint8
    DT_NM_RGS_VL_FCIB_XIX_KN_RGS_VL_XIX_Airbag_SUBCANFD01: category=ARRAY
      element ARRAY_ELEMENT: array-size=7, array-size-semantics=FIXED-SIZE, implementation-data-type=uint8
    DT_NM_RGS_VL_NM_State_XIX_NM_RGS_VL_XIX_Airbag_SUBCANFD01: implementation-data-type=uint8
    DT_NM_RGS_VL_NM_aktiv_Diag_XIX_NM_RGS_VL_XIX_Airbag_SUBCANFD01: implementation-data-type=uint8
    DT_NM_RGS_VL_NM_aktiv_KL15_XIX_NM_RGS_VL_XIX_Airbag_SUBCANFD01: implementation-data-type=uint8
    DT_NM_RGS_VL_NM_aktiv_Mot_aktiv_XIX_NM_RGS_VL_XIX_Airbag_SUBCANFD01: implementation-data-type=uint8
    DT_NM_RGS_VL_NM_aktiv_Tmin_XIX_NM_RGS_VL_XIX_Airbag_SUBCANFD01: implementation-data-type=uint8
    DT_NM_RGS_VL_SNI_10_XIX_NM_RGS_VL_XIX_Airbag_SUBCANFD01: implementation-data-type=uint16
    DT_NM_RGS_VL_UDS_CC_XIX_NM_RGS_VL_XIX_Airbag_SUBCANFD01: implementation-data-type=uint8
    DT_NM_RGS_VL_Wakeup_XIX_NM_RGS_VL_XIX_Airbag_SUBCANFD01: implementation-data-type=uint8
    DT_NM_aktiv_Ausloesefaehig_XIX_NM_Airbag_XIX_Airbag_SUBCANFD01: implementation-data-type=uint8
    DT_NM_aktiv_Gurtschloss_XIX_NM_Airbag_XIX_Airbag_SUBCANFD01: implementation-data-type=uint8
    DT_NM_aktiv_Kl15_unplausibel_XIX_NM_Airbag_XIX_Airbag_SUBCANFD01: implementation-data-type=uint8
    DT_NM_aktiv_Sitzbelegung_XIX_NM_Airbag_XIX_Airbag_SUBCANFD01: implementation-data-type=uint8
    DT_RGS_HL_Anforderung_XIX_RGS_Anf_01_XIX_Airbag_SUBCANFD01: implementation-data-type=uint8
    DT_RGS_HL_Nachlauf_2_XIX_RGS_Anf_01_XIX_Airbag_SUBCANFD01: implementation-data-type=uint8
    DT_RGS_HR_Anforderung_XIX_RGS_Anf_01_XIX_Airbag_SUBCANFD01: implementation-data-type=uint8
    DT_RGS_HR_Nachlauf_2_XIX_RGS_Anf_01_XIX_Airbag_SUBCANFD01: implementation-data-type=uint8
    DT_RGS_Nachlauf_allg_XIX_RGS_Anf_01_XIX_Airbag_SUBCANFD01: implementation-data-type=uint8
    DT_RGS_VL_Abschaltstufe_XIX_KN_RGS_VL_XIX_Airbag_SUBCANFD01: implementation-data-type=uint8
    DT_RGS_VL_Anforderung_XIX_RGS_Anf_01_XIX_Airbag_SUBCANFD01: implementation-data-type=uint8
    DT_RGS_VL_Bauteilfehler_XIX_RGS_VL_01_XIX_Airbag_SUBCANFD01: implementation-data-type=uint8
    DT_RGS_VL_Crashabschaltung_XIX_RGS_VL_01_XIX_Airbag_SUBCANFD01: implementation-data-type=uint8
    DT_RGS_VL_EEPROM_Datensatzfehler_XIX_RGS_VL_01_XIX_Airbag_SUBCANFD01: implementation-data-type=uint8
    DT_RGS_VL_Gurtbandauszug_XIX_RGS_VL_01_XIX_Airbag_SUBCANFD01: implementation-data-type=uint16
    DT_RGS_VL_Gurtgeschwindigkeit_XIX_RGS_VL_01_XIX_Airbag_SUBCANFD01: implementation-data-type=uint16
    DT_RGS_VL_InPos_XIX_RGS_VL_01_XIX_Airbag_SUBCANFD01: implementation-data-type=uint8
    DT_RGS_VL_KD_Fehler_XIX_KN_RGS_VL_XIX_Airbag_SUBCANFD01: implementation-data-type=uint8
    DT_RGS_VL_Kommunikationsfehler_ASG_XIX_RGS_VL_01_XIX_Airbag_SUBCANFD01: implementation-data-type=uint8
    DT_RGS_VL_KompSchutz_XIX_KN_RGS_VL_XIX_Airbag_SUBCANFD01: implementation-data-type=uint8
    DT_RGS_VL_Lokalaktiv_XIX_KN_RGS_VL_XIX_Airbag_SUBCANFD01: implementation-data-type=uint8
    DT_RGS_VL_Max_Gurtlosezyklen_XIX_RGS_VL_01_XIX_Airbag_SUBCANFD01: implementation-data-type=uint8
    DT_RGS_VL_Max_Haptikzyklenfehler_XIX_RGS_VL_01_XIX_Airbag_SUBCANFD01: implementation-data-type=uint8
    DT_RGS_VL_Max_Straffzyklenfehler_XIX_RGS_VL_01_XIX_Airbag_SUBCANFD01: implementation-data-type=uint8
    DT_RGS_VL_Motorfehler_XIX_RGS_VL_01_XIX_Airbag_SUBCANFD01: implementation-data-type=uint8
    DT_RGS_VL_Nachlauf_2_XIX_RGS_Anf_01_XIX_Airbag_SUBCANFD01: implementation-data-type=uint8
    DT_RGS_VL_Nachlauftyp_XIX_KN_RGS_VL_XIX_Airbag_SUBCANFD01: implementation-data-type=uint8
    DT_RGS_VL_SNI_10_XIX_KN_RGS_VL_XIX_Airbag_SUBCANFD01: implementation-data-type=uint16
    DT_RGS_VL_Status_XIX_RGS_VL_01_XIX_Airbag_SUBCANFD01: implementation-data-type=uint8
    DT_RGS_VL_Strom_XIX_RGS_VL_01_XIX_Airbag_SUBCANFD01: implementation-data-type=uint8
    DT_RGS_VL_Subsystemaktiv_XIX_KN_RGS_VL_XIX_Airbag_SUBCANFD01: implementation-data-type=uint8
    DT_RGS_VL_Temp_XIX_RGS_VL_01_XIX_Airbag_SUBCANFD01: implementation-data-type=uint8
    DT_RGS_VL_Transport_Mode_XIX_KN_RGS_VL_XIX_Airbag_SUBCANFD01: implementation-data-type=uint8
    DT_RGS_VL_Ueberspannung_XIX_RGS_VL_01_XIX_Airbag_SUBCANFD01: implementation-data-type=uint8
    DT_RGS_VL_Uebertemperatur_defekt_XIX_RGS_VL_01_XIX_Airbag_SUBCANFD01: implementation-data-type=uint8
    DT_RGS_VL_Unterspannung_XIX_RGS_VL_01_XIX_Airbag_SUBCANFD01: implementation-data-type=uint8
    DT_RGS_VL_keineStraffungUeberspg_XIX_RGS_VL_01_XIX_Airbag_SUBCANFD01: implementation-data-type=uint8
    DT_RGS_VL_keineStraffungUnterspg_XIX_RGS_VL_01_XIX_Airbag_SUBCANFD01: implementation-data-type=uint8
    DT_RGS_VL_nicht_programmiert_XIX_RGS_VL_01_XIX_Airbag_SUBCANFD01: implementation-data-type=uint8
    DT_RGS_VR_Anforderung_XIX_RGS_Anf_01_XIX_Airbag_SUBCANFD01: implementation-data-type=uint8
    DT_RGS_VR_Nachlauf_2_XIX_RGS_Anf_01_XIX_Airbag_SUBCANFD01: implementation-data-type=uint8
